VERSION ""

NS_ :

BS_:

BU_: GW ESC EPS VCU EKS AVAS

VAL_TABLE_ RollingCounter_0x132 15 "Invalid";
VAL_TABLE_ ESC_HSA_Control_Status 1 "active" 0 "inactive";
VAL_TABLE_ ESC_HSA_Status_Fault 1 " HSA Defective" 0 "HSA Normale";
VAL_TABLE_ ESC_TcsDisableSts 3 "signal invalid" 2 "reservred" 1 "disabled" 0 "enabled";
VAL_TABLE_ ESC_TcsCtrlActv 1 "active" 0 "inactive";
VAL_TABLE_ ESC_TcsFlgFlt 1 "failure" 0 "no failure";
VAL_TABLE_ ESC_EscDisableSts 1 "disabled" 0 "enabled";
VAL_TABLE_ ESC_EscCtrlActv 1 "active" 0 "inactive";
VAL_TABLE_ ESC_EscFlgFlt 1 "failure" 0 "no failure";
VAL_TABLE_ ESC_HBAFlgFlt 1 "failure" 0 "no failure";
VAL_TABLE_ ESC_HbaCtrlActv 1 "active" 0 "inactive";
VAL_TABLE_ ESC_SlopeGradeAngle 255 "Invalid";
VAL_TABLE_ ESC_MasterCylinderPressure 4095 "Invalid";
VAL_TABLE_ RollingCounter_0x142 15 "Invalid";
VAL_TABLE_ AbsDiagSessionLampReq_Reserved 1 "lamp on" 0 "lamp off";
VAL_TABLE_ ABS_AbsCtrlActv 1 "active" 0 "inactive";
VAL_TABLE_ ABS_EbdFlgFlt 1 "failure" 0 "no failure";
VAL_TABLE_ ABS_AbsFlgFlt 1 "failure" 0 "no failure";
VAL_TABLE_ ABS_ESS_Active 1 "active" 0 "inactive";
VAL_TABLE_ ABS_LowBrakeFluid 1 "failure" 0 "no failure";
VAL_TABLE_ RollingCounter_0x332 15 "Invalid";
VAL_TABLE_ ABS_LFWhlSpdRaw 32767 "Invalid";
VAL_TABLE_ ABS_LFWhlSpdRawValid 1 "Valid" 0 "Invalid";
VAL_TABLE_ ABS_RFWhlSpdRaw 32767 "Invalid";
VAL_TABLE_ ABS_RFWhlSpdRawValid 1 "Valid" 0 "Invalid";
VAL_TABLE_ RollingCounter_0x342 15 "Invalid";
VAL_TABLE_ ABS_LRWhlSpdRaw 32767 "Invalid";
VAL_TABLE_ ABS_LRWhlSpdRawValid 1 "Valid" 0 "Invalid";
VAL_TABLE_ ABS_RRWhlSpdRaw 32767 "Invalid";
VAL_TABLE_ ABS_RRWhlSpdRawValid 1 "Valid" 0 "Invalid";
VAL_TABLE_ ABS_VehSpd 32767 "Invalid";
VAL_TABLE_ ABS_VehSpdValid 1 "Valid" 0 "Invalid";
VAL_TABLE_ ABS_WssLFPulseCounter 32767 "Invalid";
VAL_TABLE_ ABS_WssLFPulseCounterValid 1 "Valid" 0 "Invalid";
VAL_TABLE_ ABS_WssRFPulseCounter 32767 "Invalid";
VAL_TABLE_ ABS_WssRFPulseCounterValid 1 "Valid" 0 "Invalid";
VAL_TABLE_ ABS_WssLRPulseCounter 32767 "Invalid";
VAL_TABLE_ ABS_WssLRPulseCounterValid 1 "Valid" 0 "Invalid";
VAL_TABLE_ ABS_WssRRPulseCounter 32767 "Invalid";
VAL_TABLE_ ABS_WssRRPulseCounterValid 1 "Valid" 0 "Invalid";
VAL_TABLE_ RollingCounter_0x3E2 15 "Invalid";
VAL_TABLE_ ESC_LateralACC 255 "Invalid";
VAL_TABLE_ ESC_LateralACC_Valid 1 "Valid" 0 "Invalid";
VAL_TABLE_ ESC_LongitudeACC 1023 "Invalid";
VAL_TABLE_ ESC_LongitudeACC_Valid 1 "Valid" 0 "Invalid";
VAL_TABLE_ ESC_VehDynYawRate 16383 "Invalid";
VAL_TABLE_ ESC_VehDynYawRate_Valid 1 "Valid" 0 "Invalid";
VAL_TABLE_ RollingCounter_0x3F2 15 "Invalid";
VAL_TABLE_ ESC_VehicleACC 1023 "Invalid";
VAL_TABLE_ ESC_VehicleACC_Valid 1 "Valid" 0 "Invalid";
VAL_TABLE_ RollingCounter_362 15 "Invalid";
VAL_TABLE_ ESC_RegenDragCtrlStatus 1 "active" 0 "inactive";
VAL_TABLE_ ESC_RegenBrakeCtrlStatus 1 "active" 0 "inactive";
VAL_TABLE_ ESC_TorqReqMode 3 "Reserved" 2 "Regen mode" 1 "TCS mode" 0 "Normal mode";
VAL_TABLE_ ESC_TorqRequestVal 65535 "Invalid";
VAL_TABLE_ ESC_FLTirePressAlarm 1 "Pressure warning" 0 "No warning";
VAL_TABLE_ ESC_FRTirePressAlarm 1 "Pressure warning" 0 "No warning";
VAL_TABLE_ ESC_RLTirePressAlarm 1 "Pressure warning" 0 "No warning";
VAL_TABLE_ ESC_RRTirePressAlarm 1 "Pressure warning" 0 "No warning";
VAL_TABLE_ ESC_iTPMS_Err 1 "Error" 0 "No error";
VAL_TABLE_ ESC_iTPMS_WarnLampAct 1 "Active" 0 "Inactive";
VAL_TABLE_ ESC_iTPMSResetProhibit 3 "prohibit 3 (System error)" 2 "prohibit 2 (Vehicle speed >0 km/h)" 1 "prohibit 1 (Tire statue is changing)" 0 "Not prohibit";
VAL_TABLE_ ESC_iTPMSResetSts 4 "Reset fail" 3 "Reset finish" 2 "Reset ongoing" 1 "Reset start" 0 "Idle";
VAL_TABLE_ Rolling_counter_0x17E 15 "Invalid";
VAL_TABLE_ SAS_SteerWheelAngle 65535 "Invalid";
VAL_TABLE_ SAS_SteeringAngleValid 1 "Valid" 0 "Invalid";
VAL_TABLE_ SAS_SASStsSnsr 1 "sensor value valid" 0 "sensor value Invalid";
VAL_TABLE_ SAS_SteerWhlRotSpd 16383 "Invalid";
VAL_TABLE_ SAS_SteerWhlRotSpdStatus 1 "Valid" 0 "Invalid";
VAL_TABLE_ SAS_Calibrated 1 "Calibrated" 0 "Not Calibrated";
VAL_TABLE_ SAS_SASFailure 1 "No Failure" 0 "Failure";
VAL_TABLE_ Rolling_counter_0x37E 15 "Invalid";
VAL_TABLE_ EPS_SteeringTorque 4095 "Invalid";
VAL_TABLE_ EPS_TorqSensorStatus 1 "Invalid" 0 "Valid";
VAL_TABLE_ EPS_EpsFailed 1 "failed" 0 "not failed";
VAL_TABLE_ EPS_Mode 3 " Invalid" 1 "low assist" 0 "full assist";
VAL_TABLE_ RollingCounter_0x108 15 "Invalid";
VAL_TABLE_ EKS_DriveModeReq_reserved 1 "press" 0 "no press";
VAL_TABLE_ EKS_TargetGearReq 7 "Reserved" 4 "Invalid" 3 "D" 2 "N" 1 "R" 0 "P reserved";
VAL_TABLE_ EKS_Fault 5 "Received Date from VCU is invalid" 4 "Supply voltage failure" 3 "Position sensor failure" 2 "CAN communication fail" 1 "Shifter failure" 0 "normal";
VAL_TABLE_ RollingCounter_0x269 15 "Invalid";
VAL_TABLE_ VCU_VehicleHVStatus 3 "Reserved" 2 "ReadyToDrive" 1 "HV On" 0 "Not ready";
VAL_TABLE_ VCU_ActualGear 7 "Fault" 6 "Reserved" 5 "Reserved" 4 "Reserved" 3 "D" 2 "N" 1 "R" 0 "P reserved";
VAL_TABLE_ VCU_ActualGearValid 1 "Invalid" 0 "Valid";
VAL_TABLE_ VCU_AccPedalPosition 255 "Invalid";
VAL_TABLE_ VCU_AccPedalPositionValid 1 "Invalid" 0 "Valid";
VAL_TABLE_ VCU_TqReductionRqstResponse 1 "active" 0 "inactive";
VAL_TABLE_ VCU_BrakePedalSts 3 "Invalid" 2 "Reserved" 1 "pressed" 0 "Not pressed";
VAL_TABLE_ Rolling_Counter_0x20C 15 "Invalid";
VAL_TABLE_ IPC_ODO 1048575 "Invalid";
VAL_TABLE_ IPC_TripA 65535 "Invalid";
VAL_TABLE_ IPC_AverageSpeedTripA 4095 "Invalid";
VAL_TABLE_ IPC_AverageConsumptionTripA 1023 "Invalid";
VAL_TABLE_ IPC_ParkBrakeSts 3 "Invalid" 2 "Reserved" 1 "Applied" 0 "Released";
VAL_TABLE_ IPC_VehSpd 32767 "Invalid";
VAL_TABLE_ IPC_TireLearningReq_reserved 3 "Reserved" 2 "Reserved" 1 "Requset" 0 "No requset";
VAL_TABLE_ IPC_TireResetReq 3 "Reserved" 2 "Reserved" 1 "Requset to reset" 0 "No requset";
VAL_TABLE_ IPC_Sec 63 "Invalid";
VAL_TABLE_ IPC_Min 63 "Invalid";
VAL_TABLE_ IPC_Hour 31 "Invalid";
VAL_TABLE_ IPC_Day 31 "Invalid";
VAL_TABLE_ IPC_Month 15 "Invalid";
VAL_TABLE_ IPC_Year 255 "Invalid";
VAL_TABLE_ IPC_SelfCheckStatus 1 "self-check finish" 0 "self-checking";
VAL_TABLE_ CCU_ExternalTemperature 255 "Invaild";
VAL_TABLE_ CCU_ExternalTemperatureFailSts 1 "invalid" 0 "valid";
VAL_TABLE_ MHU_St_DimmingIPC 15"Invalid" 14"Level 15" 13 "Level 14" 12 "Level 13" 11 "Level 12" 10 "Level 11" 9"Level 10" 8 "Level 9" 7 "Level 8" 6 "Level 7" 5 "Level 6" 4 "Level 5" 3 "Level 4" 2 "Level 3" 1"Level 2" 0"Level 1";
VAL_TABLE_ Rolling_Counter_0x403 15 "Invalid";
VAL_TABLE_ MHU_SET_TCS_OnOff 0 "OFF (keep sending for 2 seconds)" 1 "ON (keep sending for 2 seconds)" 2 "No action" 3 "Invalid";
VAL_TABLE_ MHU_SET_DrivingModeSwitch 3 "sport mode (should be hold during 1 second)" 2 "normal mode (should be hold during 1 second)" 1 "eco mode (should be hold during 1 second)" 0 "no change request";
VAL_TABLE_ MHU_SET_RegenLevel 3 "No action" 2 "High" 1 "Low" 0 "none";
VAL_TABLE_ MHU_VCU_CreepDisable_stt 0 "No request" 1 "Creep Disable request" 2 "Reserved" 3 "Invalid";
VAL_TABLE_ MHU_HVACTurnON 0 "No request" 1 "ON" 2 "Reserved" 3 "Invalid";
VAL_TABLE_ MHU_ChargeScheduleSet 0 "Disabled" 1 "Enabled" 2 "No Action" 3 "Reserved";
VAL_TABLE_ MHU_ChargingRequest 0 "Reserved" 1 "Request scheduled start charging" 2 "Request stop" 3 "No effect";
VAL_TABLE_ MHU_ValetMode_Activation 0 "Inactive" 1 "Active" 254 "Reserved" 255 "Invalid";
VAL_TABLE_ BCM_STAT_DoorAjarDriver 3 "Signal invalid" 2 "Reserved" 1 "Opened" 0 "Closed";
VAL_TABLE_ BCM_PosLmpSts 0 "OFF" 1 "ON" 2 "Fault (Reserved)" 3 "Signal Invalid";
VAL_TABLE_ Rolling_Counter_0x10a 15 "Invalid";
VAL_TABLE_ BCM_LVTop_up 1 "start Top up" 0 "stop Top up";
VAL_TABLE_ Rolling_Counter_0x112 15 "Invalid";
VAL_TABLE_ STAT_Terminal 7 "Signal invalid" 6 "Reserved" 5 "Reserved" 4 "SW update OTA (Not used in VFe34)" 3 "Engine start (eMotor running)" 2 "ON (Driver Present)" 1 "ACC (Park)" 0 "OFF(Comfort Enable)";
VAL_TABLE_ STAT_CL30s_L_Reserved 3 "Signal invalid" 2 "Failure" 1 "ON" 0 "OFF";
VAL_TABLE_ RollingCounter_0x85 15 "Invalid";
VAL_TABLE_ ACM_Crash_Sts 3 "Invalid Value" 2 "Invalid Value" 1 "Crash_Detected" 0 "No_Event";
VAL_TABLE_ ACM_Airbag_Deployment_Status 3 "Invalid Value" 2 "Invalid Value" 1 "Airbag_Deployment" 0 "No_Airbag_Deployment";
VAL_TABLE_ ACM_Crash_Intensity 7 "Invalid_Value" 6 "Invalid_Value" 5 "Invalid_Value" 4 "Invalid_Value" 3 "Crash_Intensity_3" 2 "Crash_Intensity_2" 1 "Crash_Intensity_1" 0 "No_Crash";
VAL_TABLE_ ACM_Front_Crash 3 "Invalid Value" 2 "Invalid Value" 1 "Front_Crash_Detected" 0 "No_Event";
VAL_TABLE_ ACM_DriverSide_Crash 3 "Invalid Value" 2 "Invalid Value" 1 "Driverside_Crash_Detected" 0 "No_Event";
VAL_TABLE_ ACM_PassSide_Crash 3 "Invalid Value" 2 "Invalid Value" 1 "PassSide_Crash_Detected" 0 "No_Event";
VAL_TABLE_ ACM_Rear_Crash 3 "Invalid Value" 2 "Invalid Value" 1 "Rear_Crash_Detected" 0 "No_Event";
VAL_TABLE_ ACM_Rollover_Crash 3 "Invalid Value" 2 "Invalid Value" 1 "Rollover_Crash_Detected" 0 "No_Event";
VAL_TABLE_ Rolling_Counter_0x381 15 "Invalid";
VAL_TABLE_ ACM_Seat_Occupancy_Passenger 3 "Failure" 2 "Not_Available" 1 "Seat Occupied" 0 "Seat_Not_Occupied";
VAL_TABLE_ ACM_Seat_Occupancy_2nd_Row_Dri_reserved 3 "Failure" 2 "Not_Available" 1 "Seat Occupied" 0 "Seat_Not_Occupied";
VAL_TABLE_ ACM_Seat_Occupancy_2nd_Row_Pas_reserved 3 "Failure" 2 "Not_Available" 1 "Seat Occupied" 0 "Seat_Not_Occupied";
VAL_TABLE_ ACM_Seat_Occupancy_2nd_Row_Mid_reserved 3 "Failure" 2 "Not_Available" 1 "Seat Occupied" 0 "Seat_Not_Occupied";
VAL_TABLE_ ACM_Seat_Belt_Status_Passenger 3 "Failure" 2 "Not_Available" 1 "Buckled" 0 "Not_buckled";
VAL_TABLE_ ACM_Seat_Belt_Status_Driver 3 "Failure" 2 "Not_Available" 1 "Buckled" 0 "Not_buckled";
VAL_TABLE_ ACM_Seat_Belt_Status_2nd_Row_Dri_reserved 3 "Failure" 2 "Not_Available" 1 "Buckled" 0 "Not_buckled";
VAL_TABLE_ ACM_Seat_Belt_Status_2nd_Row_Mid_reserved 3 "Failure" 2 "Not_Available" 1 "Buckled" 0 "Not_buckled";
VAL_TABLE_ ACM_Seat_Belt_Status_2nd_Row_Pas_reserved 3 "Failure" 2 "Not_Available" 1 "Buckled" 0 "Not_buckled";
VAL_TABLE_ ACM_Seat_Belt_Status_3rd_Row_Dri_reserved 3 "Failure" 2 "Not_Available" 1 "Buckled" 0 "Not_buckled";
VAL_TABLE_ ACM_Seat_Belt_Status_3rd_Row_Pas_reserved 3 "Failure" 2 "Not_Available" 1 "Buckled" 0 "Not_buckled";
VAL_TABLE_ Rolling_Counter_0x215 15 "Invalid";
VAL_TABLE_ BMS_SOE 255 "Invalid";
VAL_TABLE_ BMS_HWCrash_Sts 1 "Crash " 0 "No Crash";
VAL_TABLE_ BMS_HVIL_STS 2 "short to ground" 1 "Open & short to battery" 0 "Closed";
VAL_TABLE_ BMS_IGN_Sts 1 "ON " 0 "OFF";
VAL_TABLE_ BMS_Sys_STS 8 "Invalid" 7 "Failure, unable to operate" 6 "BCU Sleep mode" 5 "Successful Power Down" 4 "Power Down process" 3 "Successful Power Down of HV" 2 "Successful High Voltage Power Up" 1 "Self-check passes, can be high-voltage" 0 "Initialization of power on, self-checking";
VAL_TABLE_ BMS_HVOnOff_STS 3 "Fail to HV on " 2 "HV On " 1 "Precharge " 0 "HV Off";
VAL_TABLE_ BMS_Balance_STS 1 "active " 0 "Inactive";
VAL_TABLE_ BMS_SocActual_EST 1023 "Invalid";
VAL_TABLE_ BMS_BatBalance_ERR 1 "normal " 0 "Error";
VAL_TABLE_ BMS_ISU_Status 3 "Level3(<100 Ohms/V)" 2 "Level2(<200 Ohms/V)" 1 "Level1 <500 Ohms/V ~ >200 Ohms/V" 0 "Normal (> 500 Ohms/V)";
VAL_TABLE_ BMS_ERR_LEV 7 "Battery locked -Reserved" 6 "Fault, needs Shutdown and Wakeup" 5 "Emergency off condition" 4 "Delayed power down with FTTI" 3 "Power down without FTTI" 2 "Limp Home" 1 " Warning (any warning in system)" 0 "No error";
VAL_TABLE_ BMS_SOH 255 "Invalid";
VAL_TABLE_ BMS_HV_Sts 4 "AC Charge" 3 "Super Fast Charge" 2 "HV ON" 1 "Precharge" 0 "HV Off";
VAL_TABLE_ Rolling_Counter_0x1F8 15 "Invalid";
VAL_TABLE_ EDS_output_trq_FR 65535 "Invalid";
VAL_TABLE_ EDS_output_trqValid_FR 1 "valid" 0 "invalid";
VAL_TABLE_ EDS_Spd_FR 65535 "Invalid";
VAL_TABLE_ EDS_SpdValid_FR 1 "valid" 0 "invalid";
VAL_TABLE_ EDS_MotorDriveSts_FR 3 "Invaild" 2 "regen control" 1 "Drive control" 0 "Zero control";
VAL_TABLE_ EDS_Work_STS_FR 15 "invaild" 14 "power off" 13 "Failure" 12 "after run" 11 "shut down" 5 "HVReady" 4 "normal" 3 "precharge" 2 "standby" 1 "init" 0 "default";
VAL_TABLE_ EDS_powoff_req_FR 1 "(Request high voltage power down)" 0 "(No request)";
VAL_TABLE_ VCU_DriveCoolWaterPumpSts 5 "Reserved" 4 "Other error" 3 "Overtemperature" 2 "Locked-rotor" 1 "Idle" 0 "Normal";
VAL_TABLE_ VCU_DriveCoolWaterDuty 127 "Invalid";
VAL_TABLE_ VCU_BatteryWaterPumpSts_reserved 5 "Reserved" 4 "Other error" 3 "Overtemperature" 2 "Locked-rotor" 1 "Idle" 0 "Normal";
VAL_TABLE_ VCU_BatteryWaterPumpDuty_reserved 127 "Invalid";
VAL_TABLE_ VCU_DriveMode 7 "Invalid" 6 "Reserved" 5 "Reserved" 4 "Reserved" 3 "Reserved" 2 "Sport mode" 1 "ECO mode" 0 "Normal mode";
VAL_TABLE_ VCU_ActualGear 7 "Fault" 6 "Reserved" 5 "Reserved" 4 "Reserved" 3 "D" 2 "N" 1 "R" 0 "P reserved";
VAL_TABLE_ VCU_ACTGearValid 1 "nvalid" 0 "Valid";
VAL_TABLE_ VCU_AccPedal1OutRange 1 "Error" 0 "Normal";
VAL_TABLE_ VCU_AccPedal2OutRange 1 "Error" 0 "Normal";
VAL_TABLE_ VCU_BrkPedal1OutRange 1 "Error" 0 "Normal";
VAL_TABLE_ VCU_BrkPedal2OutRange 1 "Error" 0 "Normal";
VAL_TABLE_ VCU_BrkPedalPct 255 "Invalid";
VAL_TABLE_ VCU_AccPedalPosition 255 "Invalid";
VAL_TABLE_ VCU_AccPedalPositionValid 1 "Invalid" 0 "Valid";
VAL_TABLE_ VCU_SocDisplay_EST 127 "Invalid";
VAL_TABLE_ VCU_PowerLimit 1 "Limit" 0 "No Limit";
VAL_TABLE_ VCU_CruiseCtrlSts 3 "takeover mode" 2 "Pre cruise(lamp flash)" 1 "Cruise on(lamp on)" 0 "Cruise off(lamp off)";
VAL_TABLE_ VCU_LowSOC_ERR 1 "Error" 0 "No Error";
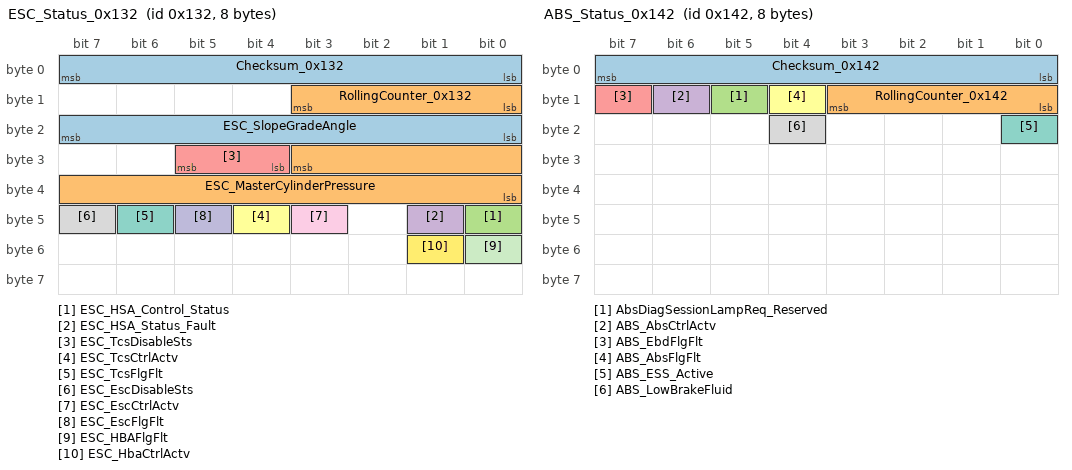
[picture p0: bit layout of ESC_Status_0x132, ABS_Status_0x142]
BO_ 306 ESC_Status_0x132: 8 ESC
 SG_ Checksum_0x132 : 7|8@0+ (1,0) [0|255] "" GW,VCU
 SG_ RollingCounter_0x132 : 11|4@0+ (1,0) [0|15] "" GW,VCU
 SG_ ESC_HSA_Control_Status : 40|1@0+ (1,0) [0|1] "" GW,VCU
 SG_ ESC_HSA_Status_Fault : 41|1@0+ (1,0) [0|1] "" GW,VCU
 SG_ ESC_TcsDisableSts : 29|2@0+ (1,0) [0|3] "" GW,VCU
 SG_ ESC_TcsCtrlActv : 44|1@0+ (1,0) [0|1] "" GW,VCU
 SG_ ESC_TcsFlgFlt : 46|1@0+ (1,0) [0|1] "" GW,VCU
 SG_ ESC_EscDisableSts : 47|1@0+ (1,0) [0|1] "" GW,VCU
 SG_ ESC_EscCtrlActv : 43|1@0+ (1,0) [0|1] "" GW,VCU
 SG_ ESC_EscFlgFlt : 45|1@0+ (1,0) [0|1] "" GW,VCU
 SG_ ESC_HBAFlgFlt : 48|1@0+ (1,0) [0|1] "" GW,VCU
 SG_ ESC_HbaCtrlActv : 49|1@0+ (1,0) [0|1] "" GW,VCU
 SG_ ESC_SlopeGradeAngle : 23|8@0+ (0.35433,-45) [-45|45] "deg" GW,VCU
 SG_ ESC_MasterCylinderPressure : 27|12@0+ (0.1,-100) [-100|309.4] "bar" GW,VCU
BO_ 322 ABS_Status_0x142: 8 ESC
 SG_ Checksum_0x142 : 7|8@0+ (1,0) [0|255] "" GW,VCU
 SG_ RollingCounter_0x142 : 11|4@0+ (1,0) [0|15] "" GW,VCU
 SG_ AbsDiagSessionLampReq_Reserved : 13|1@0+ (1,0) [0|1] "" GW,VCU
 SG_ ABS_AbsCtrlActv : 14|1@0+ (1,0) [0|1] "" GW,VCU
 SG_ ABS_EbdFlgFlt : 15|1@0+ (1,0) [0|1] "" GW,VCU
 SG_ ABS_AbsFlgFlt : 12|1@0+ (1,0) [0|1] "" GW,VCU
 SG_ ABS_ESS_Active : 16|1@0+ (1,0) [0|1] "" GW,VCU
 SG_ ABS_LowBrakeFluid : 20|1@0+ (1,0) [0|1] "" GW,VCU
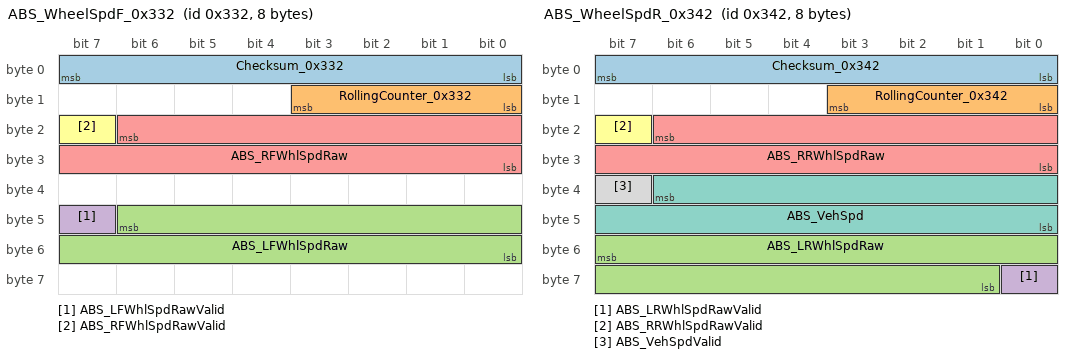
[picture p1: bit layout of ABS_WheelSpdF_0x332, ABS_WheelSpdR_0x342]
BO_ 818 ABS_WheelSpdF_0x332: 8 ESC
 SG_ Checksum_0x332 : 7|8@0+ (1,0) [0|255] "" VCU
 SG_ RollingCounter_0x332 : 11|4@0+ (1,0) [0|15] "" VCU
 SG_ ABS_LFWhlSpdRaw : 46|15@0+ (0.01,0) [0|327.66] "kph" VCU
 SG_ ABS_LFWhlSpdRawValid : 47|1@0+ (1,0) [0|1] "" VCU
 SG_ ABS_RFWhlSpdRaw : 22|15@0+ (0.01,0) [0|327.66] "kph" VCU
 SG_ ABS_RFWhlSpdRawValid : 23|1@0+ (1,0) [0|1] "" VCU
BO_ 834 ABS_WheelSpdR_0x342: 8 ESC
 SG_ Checksum_0x342 : 7|8@0+ (1,0) [0|255] "" GW,EPS,VCU,EKS,AVAS
 SG_ RollingCounter_0x342 : 11|4@0+ (1,0) [0|15] "" GW,EPS,VCU,EKS,AVAS
 SG_ ABS_LRWhlSpdRaw : 55|15@0+ (0.01,0) [0|327.66] "kph" GW,VCU,AVAS
 SG_ ABS_LRWhlSpdRawValid : 56|1@0+ (1,0) [0|1] "" GW,VCU,AVAS
 SG_ ABS_RRWhlSpdRaw : 22|15@0+ (0.01,0) [0|327.66] "kph" GW,VCU,AVAS
 SG_ ABS_RRWhlSpdRawValid : 23|1@0+ (1,0) [0|1] "" GW,VCU,AVAS
 SG_ ABS_VehSpd : 38|15@0+ (0.01,0) [0|327.66] "kph" GW,EPS,VCU,EKS,AVAS
 SG_ ABS_VehSpdValid : 39|1@0+ (1,0) [0|1] "" GW,EPS,VCU,EKS,AVAS
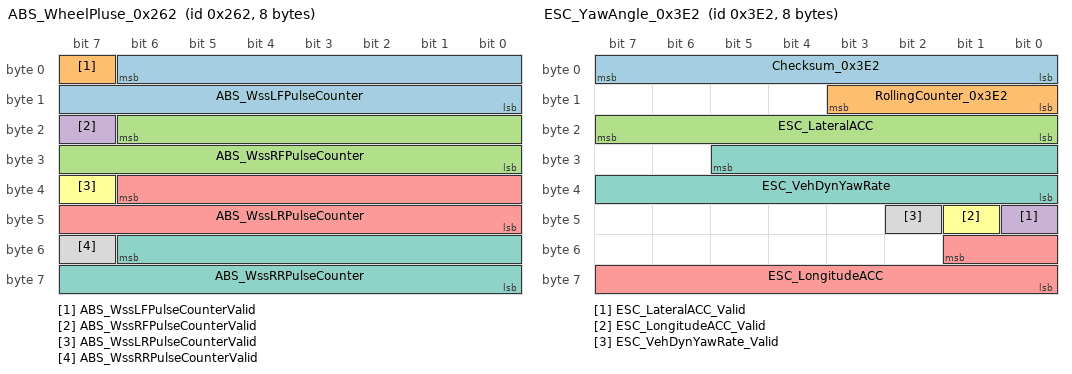
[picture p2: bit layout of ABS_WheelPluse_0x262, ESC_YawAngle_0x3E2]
BO_ 610 ABS_WheelPluse_0x262: 8 ESC
 SG_ ABS_WssLFPulseCounter : 6|15@0+ (1,0) [0|32766] "pluse" Vector__XXX
 SG_ ABS_WssLFPulseCounterValid : 7|1@0+ (1,0) [0|1] "" Vector__XXX
 SG_ ABS_WssRFPulseCounter : 22|15@0+ (1,0) [0|32766] "pluse" Vector__XXX
 SG_ ABS_WssRFPulseCounterValid : 23|1@0+ (1,0) [0|1] "" Vector__XXX
 SG_ ABS_WssLRPulseCounter : 38|15@0+ (1,0) [0|32766] "pluse" Vector__XXX
 SG_ ABS_WssLRPulseCounterValid : 39|1@0+ (1,0) [0|1] "" Vector__XXX
 SG_ ABS_WssRRPulseCounter : 54|15@0+ (1,0) [0|32766] "pluse" Vector__XXX
 SG_ ABS_WssRRPulseCounterValid : 55|1@0+ (1,0) [0|1] "" Vector__XXX
BO_ 994 ESC_YawAngle_0x3E2: 8 ESC
 SG_ Checksum_0x3E2 : 7|8@0+ (1,0) [0|255] "" GW
 SG_ RollingCounter_0x3E2 : 11|4@0+ (1,0) [0|15] "" GW
 SG_ ESC_LateralACC : 23|8@0+ (0.01587,-2.0193) [-2.0193|2.0193] "g" GW
 SG_ ESC_LateralACC_Valid : 40|1@0+ (1,0) [0|1] "" GW
 SG_ ESC_LongitudeACC : 49|10@0+ (0.00392,-1.9929) [-1.9929|1.9929] "g" GW
 SG_ ESC_LongitudeACC_Valid : 41|1@0+ (1,0) [0|1] "" GW
 SG_ ESC_VehDynYawRate : 29|14@0+ (0.03125,-256) [-256|255.96875] "deg/s" GW
 SG_ ESC_VehDynYawRate_Valid : 42|1@0+ (1,0) [0|1] "" GW
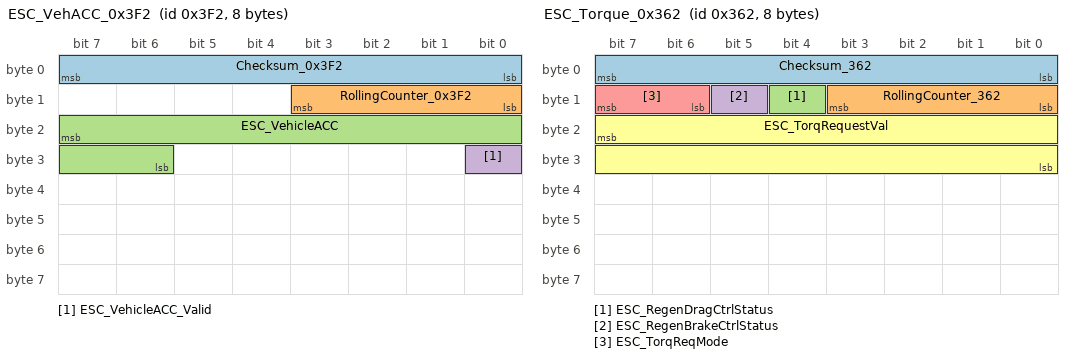
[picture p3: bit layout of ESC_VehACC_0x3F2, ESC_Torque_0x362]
BO_ 1010 ESC_VehACC_0x3F2: 8 ESC
 SG_ Checksum_0x3F2 : 7|8@0+ (1,0) [0|255] "" Vector__XXX
 SG_ RollingCounter_0x3F2 : 11|4@0+ (1,0) [0|15] "" Vector__XXX
 SG_ ESC_VehicleACC : 23|10@0+ (0.00392,-1.9929) [-1.9929|1.9929] "g" Vector__XXX
 SG_ ESC_VehicleACC_Valid : 24|1@0+ (1,0) [0|1] "" Vector__XXX
BO_ 866 ESC_Torque_0x362: 8 ESC
 SG_ Checksum_362 : 7|8@0+ (1,0) [0|255] "" VCU
 SG_ RollingCounter_362 : 11|4@0+ (1,0) [0|15] "" VCU
 SG_ ESC_RegenDragCtrlStatus : 12|1@0+ (1,0) [0|1] "" VCU
 SG_ ESC_RegenBrakeCtrlStatus : 13|1@0+ (1,0) [0|1] "" VCU
 SG_ ESC_TorqReqMode : 15|2@0+ (1,0) [0|3] "" VCU
 SG_ ESC_TorqRequestVal : 23|16@0+ (0.05,-1000) [-1000|1000] "Nm" VCU
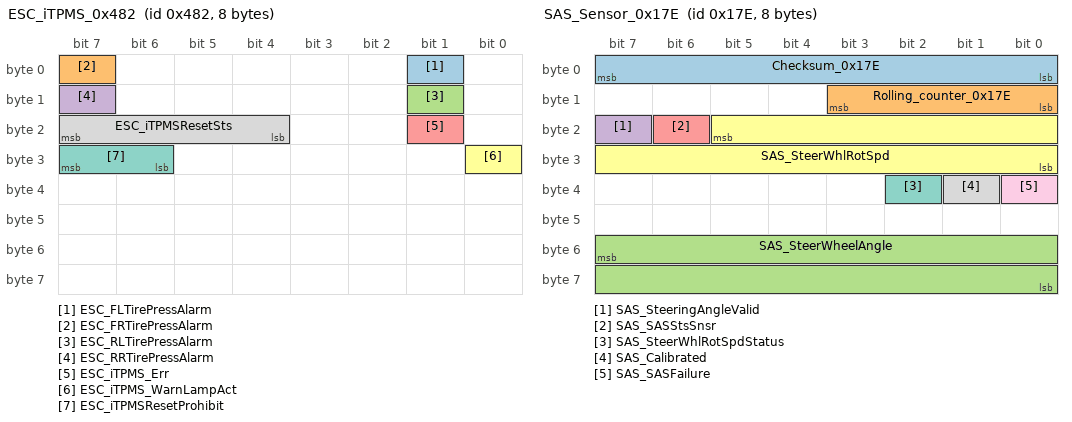
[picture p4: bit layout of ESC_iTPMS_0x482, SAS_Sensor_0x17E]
BO_ 1154 ESC_iTPMS_0x482: 8 ESC
 SG_ ESC_FLTirePressAlarm : 1|1@0+ (1,0) [0|1] "" GW
 SG_ ESC_FRTirePressAlarm : 7|1@0+ (1,0) [0|1] "" GW
 SG_ ESC_RLTirePressAlarm : 9|1@0+ (1,0) [0|1] "" GW
 SG_ ESC_RRTirePressAlarm : 15|1@0+ (1,0) [0|1] "" GW
 SG_ ESC_iTPMS_Err : 17|1@0+ (1,0) [0|1] "" GW
 SG_ ESC_iTPMS_WarnLampAct : 24|1@0+ (1,0) [0|1] "" GW
 SG_ ESC_iTPMSResetProhibit : 31|2@0+ (1,0) [0|3] "" GW
 SG_ ESC_iTPMSResetSts : 23|4@0+ (1,0) [0|15] "" GW
BO_ 382 SAS_Sensor_0x17E: 8 EPS
 SG_ Checksum_0x17E : 7|8@0+ (1,0) [0|255] "" GW,ESC
 SG_ Rolling_counter_0x17E : 11|4@0+ (1,0) [0|15] "" GW,ESC
 SG_ SAS_SteerWheelAngle : 55|16@0+ (0.0238,-780) [-780|779.7] "deg" GW,ESC
 SG_ SAS_SteeringAngleValid : 23|1@0+ (1,0) [0|1] "" GW,ESC
 SG_ SAS_SASStsSnsr : 22|1@0+ (1,0) [0|1] "" GW,ESC
 SG_ SAS_SteerWhlRotSpd : 21|14@0+ (0.125,-1024) [-1024|1023.75] "degs" GW,ESC
 SG_ SAS_SteerWhlRotSpdStatus : 34|1@0+ (1,0) [0|1] "" GW,ESC
 SG_ SAS_Calibrated : 33|1@0+ (1,0) [0|1] "" GW,ESC
 SG_ SAS_SASFailure : 32|1@0+ (1,0) [0|1] "" GW,ESC
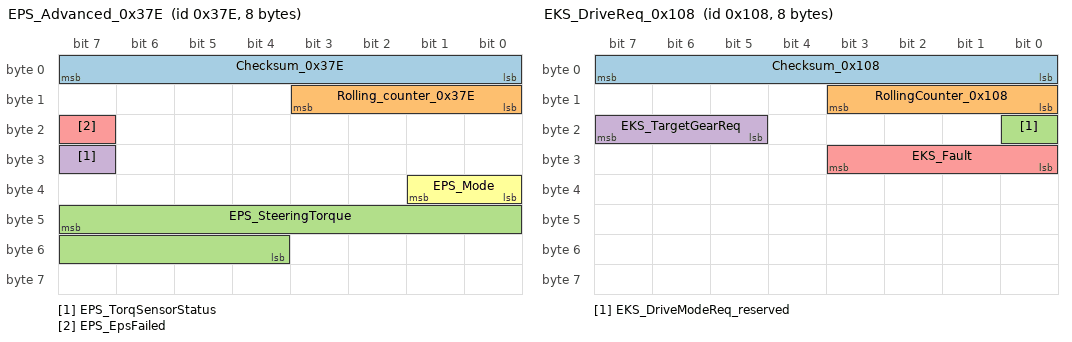
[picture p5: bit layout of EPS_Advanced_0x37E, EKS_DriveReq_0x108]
BO_ 894 EPS_Advanced_0x37E: 8 EPS
 SG_ Checksum_0x37E : 7|8@0+ (1,0) [0|255] "" GW,VCU
 SG_ Rolling_counter_0x37E : 11|4@0+ (1,0) [0|15] "" GW,VCU
 SG_ EPS_SteeringTorque : 47|12@0+ (0.01,-20.47) [-20.47|20.47] "Nm" GW,VCU
 SG_ EPS_TorqSensorStatus : 31|1@0+ (1,0) [0|1] "" GW,VCU
 SG_ EPS_EpsFailed : 23|1@0+ (1,0) [0|1] "" GW,VCU
 SG_ EPS_Mode : 33|2@0+ (1,0) [0|3] "" GW,VCU
BO_ 264 EKS_DriveReq_0x108: 8 EKS
 SG_ Checksum_0x108 : 7|8@0+ (1,0) [0|255] "" VCU
 SG_ RollingCounter_0x108 : 11|4@0+ (1,0) [0|15] "" VCU
 SG_ EKS_DriveModeReq_reserved : 16|1@0+ (1,0) [0|1] "" VCU
 SG_ EKS_TargetGearReq : 23|3@0+ (1,0) [0|7] "" VCU
 SG_ EKS_Fault : 27|4@0+ (1,0) [0|4] "" VCU
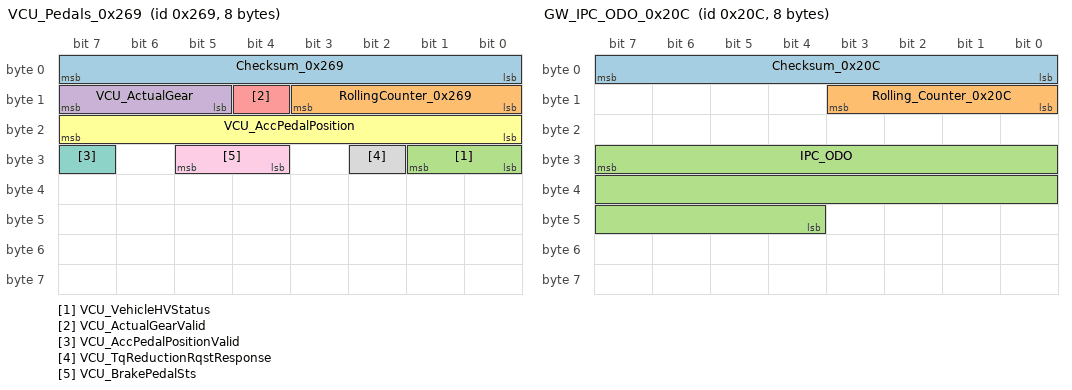
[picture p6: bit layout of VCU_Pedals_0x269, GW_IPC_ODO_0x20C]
BO_ 617 VCU_Pedals_0x269: 8 VCU
 SG_ Checksum_0x269 : 7|8@0+ (1,0) [0|255] "" GW,ESC,EPS,EKS,AVAS
 SG_ RollingCounter_0x269 : 11|4@0+ (1,0) [0|15] "" GW,ESC,EPS,EKS,AVAS
 SG_ VCU_VehicleHVStatus : 25|2@0+ (1,0) [0|3] "" GW,ESC,EPS,EKS,AVAS
 SG_ VCU_ActualGear : 15|3@0+ (1,0) [0|7] "" GW,ESC,EKS,AVAS
 SG_ VCU_ActualGearValid : 12|1@0+ (1,0) [0|1] "" GW,ESC,EKS,AVAS
 SG_ VCU_AccPedalPosition : 23|8@0+ (0.4,0) [0|100] "%" GW,ESC
 SG_ VCU_AccPedalPositionValid : 31|1@0+ (1,0) [0|1] "" GW,ESC
 SG_ VCU_TqReductionRqstResponse : 26|1@0+ (1,0) [0|1] "" GW
 SG_ VCU_BrakePedalSts : 29|2@0+ (1,0) [0|3] "" GW,ESC
BO_ 524 GW_IPC_ODO_0x20C: 8 GW
 SG_ Checksum_0x20C : 7|8@0+ (1,0) [0|255] "" ESC,EPS,VCU,EKS,AVAS
 SG_ Rolling_Counter_0x20C : 11|4@0+ (1,0) [0|15] "" ESC,EPS,VCU,EKS,AVAS
 SG_ IPC_ODO : 31|20@0+ (1,0) [0|999999] "km" ESC,EPS,VCU,EKS,AVAS
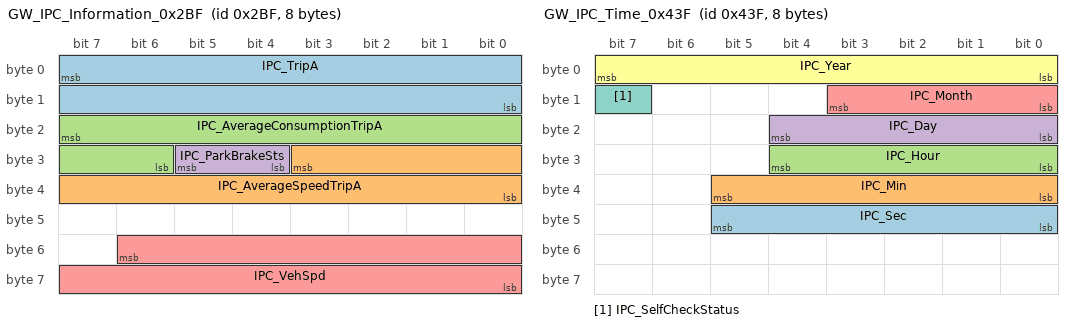
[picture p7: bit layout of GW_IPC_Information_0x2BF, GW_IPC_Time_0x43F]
BO_ 703 GW_IPC_Information_0x2BF: 8 GW
 SG_ IPC_TripA : 7|16@0+ (0.1,0) [0|999.9] "km" Vector__XXX
 SG_ IPC_AverageSpeedTripA : 27|12@0+ (0.0625,0) [0|250] "km/h" Vector__XXX
 SG_ IPC_AverageConsumptionTripA : 23|10@0+ (0.1,0) [0|100] "kwh/100km" Vector__XXX
 SG_ IPC_ParkBrakeSts : 29|2@0+ (1,0) [0|3] "" ESC
 SG_ IPC_VehSpd : 54|15@0+ (0.01,0) [0|327.66] "kph" Vector__XXX
BO_ 735 GW_IPC_TPMSReq_0x2DF: 8 GW
 SG_ IPC_TireLearningReq_reserved : 1|2@0+ (1,0) [0|3] "" Vector__XXX
 SG_ IPC_TireResetReq : 7|2@0+ (1,0) [0|3] "" ESC
BO_ 1087 GW_IPC_Time_0x43F: 8 GW
 SG_ IPC_Sec : 45|6@0+ (1,0) [0|59] "second" ESC,EPS,EKS
 SG_ IPC_Min : 37|6@0+ (1,0) [0|59] "min" ESC,EPS,EKS
 SG_ IPC_Hour : 28|5@0+ (1,0) [0|23] "hour" ESC,EPS,EKS
 SG_ IPC_Day : 20|5@0+ (1,0) [1|31] "" ESC,EPS,EKS
 SG_ IPC_Month : 11|4@0+ (1,0) [1|12] "" ESC,EPS,EKS
 SG_ IPC_Year : 7|8@0+ (1,2000) [2000|2255] "" ESC,EPS,EKS
 SG_ IPC_SelfCheckStatus : 15|1@0+ (1,0) [0|1] "" ESC,EPS,EKS
BO_ 814 GW_CCU_Info_0x32E: 8 GW
 SG_ CCU_ExternalTemperature : 7|8@0+ (0.5,-40) [-40|87] "°C" EPS,EKS,AVAS
 SG_ CCU_ExternalTemperatureFailSts : 8|1@0+ (1,0) [0|1] "" EPS,EKS,AVAS
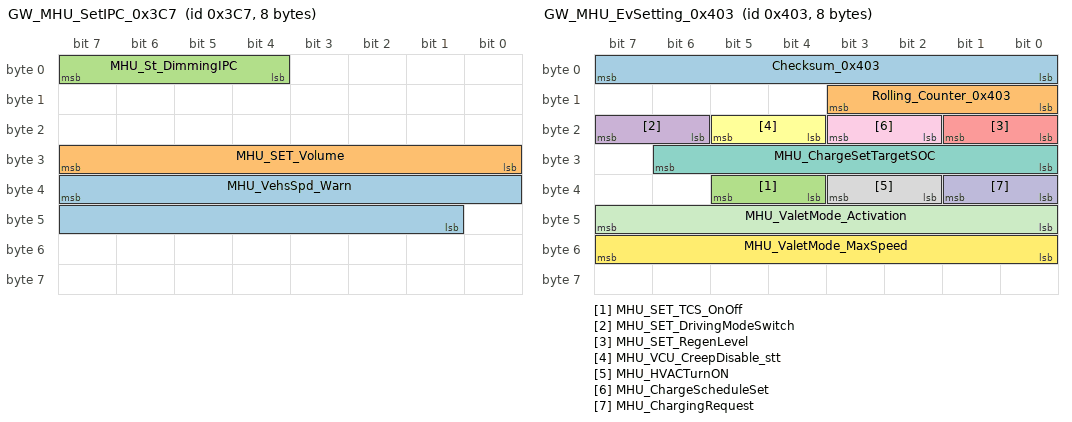
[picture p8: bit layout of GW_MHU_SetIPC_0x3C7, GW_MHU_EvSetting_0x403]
BO_ 967 GW_MHU_SetIPC_0x3C7: 8 GW
 SG_ MHU_VehsSpd_Warn : 39|15@0+ (0.01,0) [0|120] "" EKS
 SG_ MHU_SET_Volume : 31|8@0+ (1,0) [0|32] "" Vector__XXX
 SG_ MHU_St_DimmingIPC : 7|4@0+ (1,0) [0|15] "" EKS
BO_ 1027 GW_MHU_EvSetting_0x403: 8 GW
 SG_ Checksum_0x403 : 7|8@0+ (1,0) [0|255] "" ESC
 SG_ Rolling_Counter_0x403 : 11|4@0+ (1,0) [0|15] "" ESC
 SG_ MHU_SET_TCS_OnOff : 37|2@0+ (1,0) [0|3] "" ESC
 SG_ MHU_SET_DrivingModeSwitch : 23|2@0+ (1,0) [0|3] "" Vector__XXX
 SG_ MHU_SET_RegenLevel : 17|2@0+ (1,0) [0|3] "" Vector__XXX
 SG_ MHU_VCU_CreepDisable_stt : 21|2@0+ (1,0) [0|3] "" Vector__XXX
 SG_ MHU_ChargeSetTargetSOC : 30|7@0+ (1,0) [10|100] "Percentage" Vector__XXX
 SG_ MHU_HVACTurnON : 35|2@0+ (1,0) [0|3] "" Vector__XXX
 SG_ MHU_ChargeScheduleSet : 19|2@0+ (1,0) [0|3] "" Vector__XXX
 SG_ MHU_ChargingRequest : 33|2@0+ (1,0) [0|3] "" Vector__XXX
 SG_ MHU_ValetMode_Activation : 47|8@0+ (1,0) [0|254] "" Vector__XXX
 SG_ MHU_ValetMode_MaxSpeed : 55|8@0+ (1,0) [0|254] "kph" Vector__XXX
BO_ 848 GW_Body_Switch_0x350: 8 GW
 SG_ BCM_STAT_DoorAjarDriver : 7|2@0+ (1,0) [0|3] "Bit" ESC
 SG_ BCM_PosLmpSts : 15|2@0+ (1,0) [0|3] "" EKS
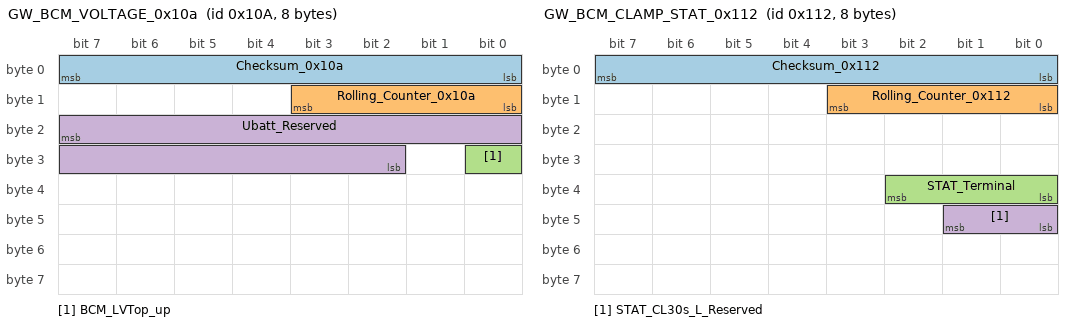
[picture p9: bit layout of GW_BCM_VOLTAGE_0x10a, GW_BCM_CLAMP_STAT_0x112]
BO_ 266 GW_BCM_VOLTAGE_0x10a: 8 GW
 SG_ Checksum_0x10a : 7|8@0+ (1,0) [0|255] "" ESC,EPS,EKS,AVAS
 SG_ Rolling_Counter_0x10a : 11|4@0+ (1,0) [0|15] "" ESC,EPS,EKS,AVAS
 SG_ BCM_LVTop_up : 24|1@0+ (1,0) [0|1] "" Vector__XXX
 SG_ Ubatt_Reserved : 23|14@0+ (0.001,3) [3|18] "V" ESC,EPS,EKS,AVAS
BO_ 274 GW_BCM_CLAMP_STAT_0x112: 8 GW
 SG_ Checksum_0x112 : 7|8@0+ (1,0) [0|255] "" ESC,EPS,EKS,AVAS
 SG_ Rolling_Counter_0x112 : 11|4@0+ (1,0) [0|15] "" ESC,EPS,EKS,AVAS
 SG_ STAT_Terminal : 34|3@0+ (1,0) [0|7] "Bit" ESC,EPS,EKS,AVAS
 SG_ STAT_CL30s_L_Reserved : 41|2@0+ (1,0) [0|3] "Bit" AVAS
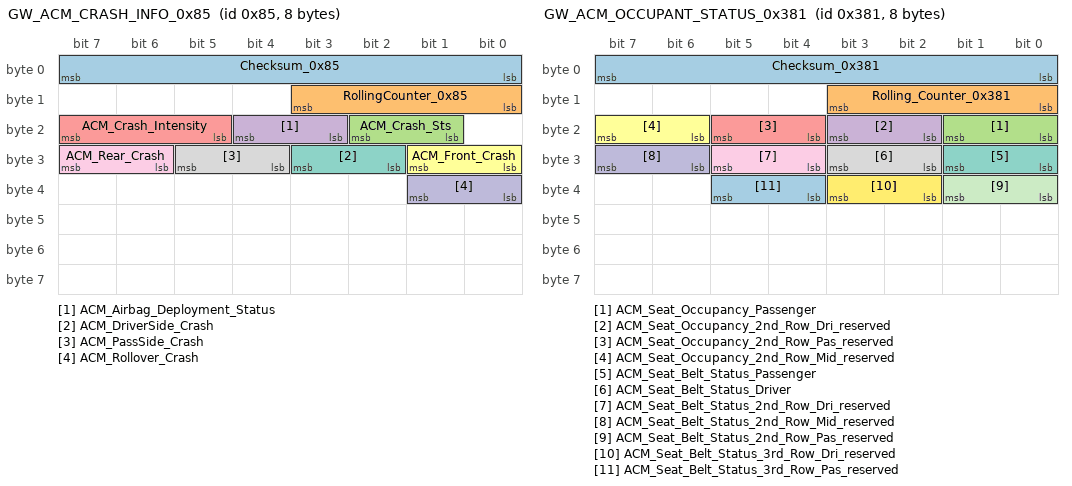
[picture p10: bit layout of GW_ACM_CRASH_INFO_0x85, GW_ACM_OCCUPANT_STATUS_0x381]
BO_ 133 GW_ACM_CRASH_INFO_0x85: 8 GW
 SG_ Checksum_0x85 : 7|8@0+ (1,0) [0|255] "" VCU
 SG_ RollingCounter_0x85 : 11|4@0+ (1,0) [0|15] "" VCU
 SG_ ACM_Crash_Sts : 18|2@0+ (1,0) [0|3] "" VCU
 SG_ ACM_Airbag_Deployment_Status : 20|2@0+ (1,0) [0|3] "" Vector__XXX
 SG_ ACM_Crash_Intensity : 23|3@0+ (1,0) [0|7] "" Vector__XXX
 SG_ ACM_Front_Crash : 25|2@0+ (1,0) [0|3] "" Vector__XXX
 SG_ ACM_DriverSide_Crash : 27|2@0+ (1,0) [0|3] "" Vector__XXX
 SG_ ACM_PassSide_Crash : 29|2@0+ (1,0) [0|3] "" Vector__XXX
 SG_ ACM_Rear_Crash : 31|2@0+ (1,0) [0|3] "" Vector__XXX
 SG_ ACM_Rollover_Crash : 33|2@0+ (1,0) [0|3] "" Vector__XXX
BO_ 897 GW_ACM_OCCUPANT_STATUS_0x381: 8 GW
 SG_ Checksum_0x381 : 7|8@0+ (1,0) [0|255] "" VCU
 SG_ Rolling_Counter_0x381 : 11|4@0+ (1,0) [0|15] "" VCU
 SG_ ACM_Seat_Occupancy_Passenger : 17|2@0+ (1,0) [0|3] "" VCU
 SG_ ACM_Seat_Occupancy_2nd_Row_Dri_reserved : 19|2@0+ (1,0) [0|3] "" VCU
 SG_ ACM_Seat_Occupancy_2nd_Row_Pas_reserved : 21|2@0+ (1,0) [0|3] "" VCU
 SG_ ACM_Seat_Occupancy_2nd_Row_Mid_reserved : 23|2@0+ (1,0) [0|3] "" VCU
 SG_ ACM_Seat_Belt_Status_Passenger : 25|2@0+ (1,0) [0|3] "" VCU
 SG_ ACM_Seat_Belt_Status_Driver : 27|2@0+ (1,0) [0|3] "" VCU
 SG_ ACM_Seat_Belt_Status_2nd_Row_Dri_reserved : 29|2@0+ (1,0) [0|3] "" VCU
 SG_ ACM_Seat_Belt_Status_2nd_Row_Mid_reserved : 31|2@0+ (1,0) [0|3] "" VCU
 SG_ ACM_Seat_Belt_Status_2nd_Row_Pas_reserved : 33|2@0+ (1,0) [0|3] "" VCU
 SG_ ACM_Seat_Belt_Status_3rd_Row_Dri_reserved : 35|2@0+ (1,0) [0|3] "" VCU
 SG_ ACM_Seat_Belt_Status_3rd_Row_Pas_reserved : 37|2@0+ (1,0) [0|3] "" VCU
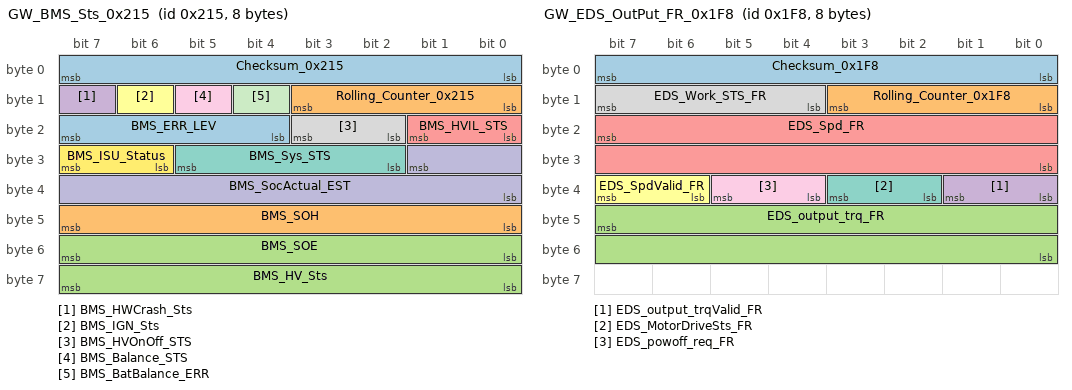
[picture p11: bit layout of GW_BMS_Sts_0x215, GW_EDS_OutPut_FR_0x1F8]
BO_ 533 GW_BMS_Sts_0x215: 8 GW
 SG_ Checksum_0x215 : 7|8@0+ (1,0) [0|255] "" EKS
 SG_ Rolling_Counter_0x215 : 11|4@0+ (1,0) [0|15] "" EKS
 SG_ BMS_SOE : 55|8@0+ (0.5,0) [0|100] "%" Vector__XXX
 SG_ BMS_HWCrash_Sts : 15|1@0+ (1,0) [0|1] "" Vector__XXX
 SG_ BMS_HVIL_STS : 17|2@0+ (1,0) [0|3] "" Vector__XXX
 SG_ BMS_IGN_Sts : 14|1@0+ (1,0) [0|1] "" Vector__XXX
 SG_ BMS_Sys_STS : 29|4@0+ (1,0) [0|15] "" Vector__XXX
 SG_ BMS_HVOnOff_STS : 19|2@0+ (1,0) [0|3] "" EKS
 SG_ BMS_Balance_STS : 13|1@0+ (1,0) [0|1] "" Vector__XXX
 SG_ BMS_SocActual_EST : 25|10@0+ (0.1,0) [0|100] "percent" Vector__XXX
 SG_ BMS_BatBalance_ERR : 12|1@0+ (1,0) [0|1] "" Vector__XXX
 SG_ BMS_ISU_Status : 31|2@0+ (1,0) [0|3] "" Vector__XXX
 SG_ BMS_ERR_LEV : 23|4@0+ (1,0) [0|15] "" Vector__XXX
 SG_ BMS_SOH : 47|8@0+ (0.5,0) [0|100] "%" Vector__XXX
 SG_ BMS_HV_Sts : 63|8@0+ (1,0) [0|255] "" Vector__XXX
BO_ 504 GW_EDS_OutPut_FR_0x1F8: 8 GW
 SG_ Checksum_0x1F8 : 7|8@0+ (1,0) [0|255] "" ESC
 SG_ Rolling_Counter_0x1F8 : 11|4@0+ (1,0) [0|15] "" ESC
 SG_ EDS_output_trq_FR : 47|16@0+ (1,-2000) [-2000|2000] "Nm" ESC
 SG_ EDS_output_trqValid_FR : 33|2@0+ (1,0) [0|1] "" ESC
 SG_ EDS_Spd_FR : 23|16@0+ (1,-20000) [-20000|20000] "rpm" ESC
 SG_ EDS_SpdValid_FR : 39|2@0+ (1,0) [0|1] "" ESC
 SG_ EDS_MotorDriveSts_FR : 35|2@0+ (1,0) [0|3] "" ESC
 SG_ EDS_Work_STS_FR : 15|4@0+ (1,0) [0|15] "" ESC
 SG_ EDS_powoff_req_FR : 37|2@0+ (1,0) [0|1] "" ESC
BO_ 889 GW_VCU_Sts2_0x379: 8 GW
 SG_ VCU_DriveCoolWaterPumpSts : 2|3@0+ (1,0) [0|5] "" Vector__XXX
 SG_ VCU_DriveCoolWaterDuty : 14|7@0+ (1,0) [0|100] "%" Vector__XXX
 SG_ VCU_BatteryWaterPumpSts_reserved : 30|3@0+ (1,0) [0|7] "" Vector__XXX
 SG_ VCU_BatteryWaterPumpDuty_reserved : 22|7@0+ (1,0) [0|100] "%" Vector__XXX
 SG_ VCU_DriveMode : 5|3@0+ (1,0) [0|7] "" Vector__XXX
 SG_ VCU_ActualGear : 26|3@0+ (1,0) [0|7] "" AVAS
 SG_ VCU_ACTGearValid : 27|1@0+ (1,0) [0|1] "" AVAS
 SG_ VCU_AccPedal1OutRange : 31|1@0+ (1,0) [0|1] "" Vector__XXX
 SG_ VCU_AccPedal2OutRange : 33|1@0+ (1,0) [0|1] "" Vector__XXX
 SG_ VCU_BrkPedal1OutRange : 35|1@0+ (1,0) [0|1] "" Vector__XXX
 SG_ VCU_BrkPedal2OutRange : 37|1@0+ (1,0) [0|1] "" Vector__XXX
 SG_ VCU_BrkPedalPct : 47|8@0+ (0.4,0) [0|100] "%" Vector__XXX
 SG_ VCU_AccPedalPosition : 55|8@0+ (0.4,0) [0|100] "%" Vector__XXX
 SG_ VCU_AccPedalPositionValid : 63|1@0+ (1,0) [0|1] "" Vector__XXX
 SG_ VCU_SocDisplay_EST : 62|7@0+ (1,0) [0|100] "%" Vector__XXX
 SG_ VCU_PowerLimit : 15|1@0+ (1,0) [0|1] "" Vector__XXX
 SG_ VCU_CruiseCtrlSts : 39|2@0+ (1,0) [0|3] "" ESC
 SG_ VCU_LowSOC_ERR : 23|1@0+ (1,0) [0|1] "" Vector__XXX
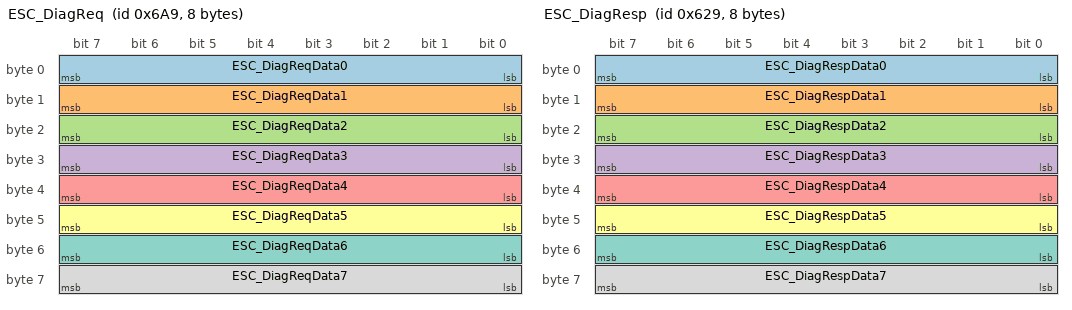
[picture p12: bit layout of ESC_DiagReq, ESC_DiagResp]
BO_ 1705 ESC_DiagReq: 8 GW
 SG_ ESC_DiagReqData0 : 7|8@0+ (1,0) [0|255] "" ESC
 SG_ ESC_DiagReqData1 : 15|8@0+ (1,0) [0|255] "" ESC
 SG_ ESC_DiagReqData2 : 23|8@0+ (1,0) [0|255] "" ESC
 SG_ ESC_DiagReqData3 : 31|8@0+ (1,0) [0|255] "" ESC
 SG_ ESC_DiagReqData4 : 39|8@0+ (1,0) [0|255] "" ESC
 SG_ ESC_DiagReqData5 : 47|8@0+ (1,0) [0|255] "" ESC
 SG_ ESC_DiagReqData6 : 55|8@0+ (1,0) [0|255] "" ESC
 SG_ ESC_DiagReqData7 : 63|8@0+ (1,0) [0|255] "" ESC
BO_ 1577 ESC_DiagResp: 8 ESC
 SG_ ESC_DiagRespData0 : 7|8@0+ (1,0) [0|255] "" GW
 SG_ ESC_DiagRespData1 : 15|8@0+ (1,0) [0|255] "" GW
 SG_ ESC_DiagRespData2 : 23|8@0+ (1,0) [0|255] "" GW
 SG_ ESC_DiagRespData3 : 31|8@0+ (1,0) [0|255] "" GW
 SG_ ESC_DiagRespData4 : 39|8@0+ (1,0) [0|255] "" GW
 SG_ ESC_DiagRespData5 : 47|8@0+ (1,0) [0|255] "" GW
 SG_ ESC_DiagRespData6 : 55|8@0+ (1,0) [0|255] "" GW
 SG_ ESC_DiagRespData7 : 63|8@0+ (1,0) [0|255] "" GW
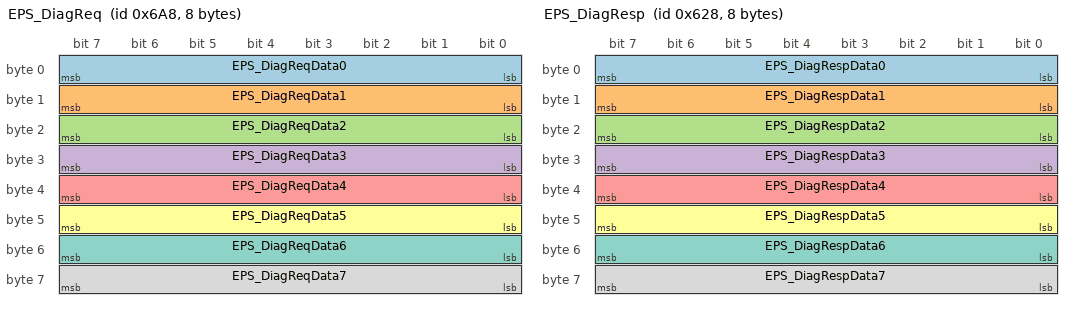
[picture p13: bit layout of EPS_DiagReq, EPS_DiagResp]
BO_ 1704 EPS_DiagReq: 8 GW
 SG_ EPS_DiagReqData0 : 7|8@0+ (1,0) [0|255] "" EPS
 SG_ EPS_DiagReqData1 : 15|8@0+ (1,0) [0|255] "" EPS
 SG_ EPS_DiagReqData2 : 23|8@0+ (1,0) [0|255] "" EPS
 SG_ EPS_DiagReqData3 : 31|8@0+ (1,0) [0|255] "" EPS
 SG_ EPS_DiagReqData4 : 39|8@0+ (1,0) [0|255] "" EPS
 SG_ EPS_DiagReqData5 : 47|8@0+ (1,0) [0|255] "" EPS
 SG_ EPS_DiagReqData6 : 55|8@0+ (1,0) [0|255] "" EPS
 SG_ EPS_DiagReqData7 : 63|8@0+ (1,0) [0|255] "" EPS
BO_ 1576 EPS_DiagResp: 8 EPS
 SG_ EPS_DiagRespData0 : 7|8@0+ (1,0) [0|255] "" GW
 SG_ EPS_DiagRespData1 : 15|8@0+ (1,0) [0|255] "" GW
 SG_ EPS_DiagRespData2 : 23|8@0+ (1,0) [0|255] "" GW
 SG_ EPS_DiagRespData3 : 31|8@0+ (1,0) [0|255] "" GW
 SG_ EPS_DiagRespData4 : 39|8@0+ (1,0) [0|255] "" GW
 SG_ EPS_DiagRespData5 : 47|8@0+ (1,0) [0|255] "" GW
 SG_ EPS_DiagRespData6 : 55|8@0+ (1,0) [0|255] "" GW
 SG_ EPS_DiagRespData7 : 63|8@0+ (1,0) [0|255] "" GW
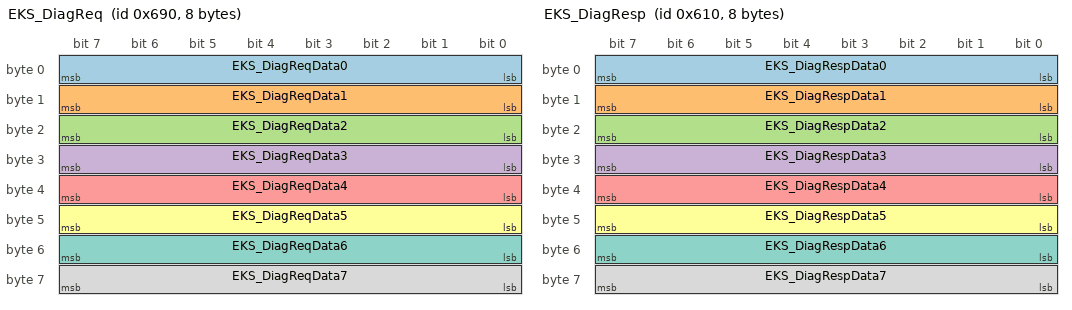
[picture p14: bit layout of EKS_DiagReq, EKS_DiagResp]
BO_ 1680 EKS_DiagReq: 8 GW
 SG_ EKS_DiagReqData0 : 7|8@0+ (1,0) [0|255] "" EKS
 SG_ EKS_DiagReqData1 : 15|8@0+ (1,0) [0|255] "" EKS
 SG_ EKS_DiagReqData2 : 23|8@0+ (1,0) [0|255] "" EKS
 SG_ EKS_DiagReqData3 : 31|8@0+ (1,0) [0|255] "" EKS
 SG_ EKS_DiagReqData4 : 39|8@0+ (1,0) [0|255] "" EKS
 SG_ EKS_DiagReqData5 : 47|8@0+ (1,0) [0|255] "" EKS
 SG_ EKS_DiagReqData6 : 55|8@0+ (1,0) [0|255] "" EKS
 SG_ EKS_DiagReqData7 : 63|8@0+ (1,0) [0|255] "" EKS
BO_ 1552 EKS_DiagResp: 8 EKS
 SG_ EKS_DiagRespData0 : 7|8@0+ (1,0) [0|255] "" GW
 SG_ EKS_DiagRespData1 : 15|8@0+ (1,0) [0|255] "" GW
 SG_ EKS_DiagRespData2 : 23|8@0+ (1,0) [0|255] "" GW
 SG_ EKS_DiagRespData3 : 31|8@0+ (1,0) [0|255] "" GW
 SG_ EKS_DiagRespData4 : 39|8@0+ (1,0) [0|255] "" GW
 SG_ EKS_DiagRespData5 : 47|8@0+ (1,0) [0|255] "" GW
 SG_ EKS_DiagRespData6 : 55|8@0+ (1,0) [0|255] "" GW
 SG_ EKS_DiagRespData7 : 63|8@0+ (1,0) [0|255] "" GW
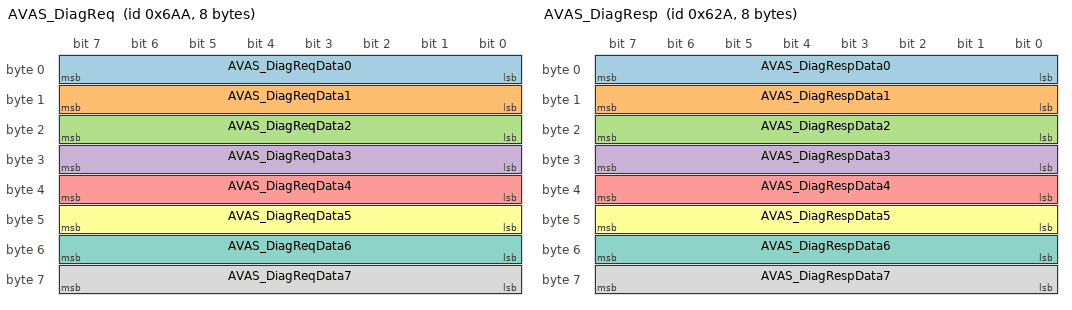
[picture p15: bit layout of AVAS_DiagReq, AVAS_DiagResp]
BO_ 1706 AVAS_DiagReq: 8 GW
 SG_ AVAS_DiagReqData0 : 7|8@0+ (1,0) [0|255] "" AVAS
 SG_ AVAS_DiagReqData1 : 15|8@0+ (1,0) [0|255] "" AVAS
 SG_ AVAS_DiagReqData2 : 23|8@0+ (1,0) [0|255] "" AVAS
 SG_ AVAS_DiagReqData3 : 31|8@0+ (1,0) [0|255] "" AVAS
 SG_ AVAS_DiagReqData4 : 39|8@0+ (1,0) [0|255] "" AVAS
 SG_ AVAS_DiagReqData5 : 47|8@0+ (1,0) [0|255] "" AVAS
 SG_ AVAS_DiagReqData6 : 55|8@0+ (1,0) [0|255] "" AVAS
 SG_ AVAS_DiagReqData7 : 63|8@0+ (1,0) [0|255] "" AVAS
BO_ 1578 AVAS_DiagResp: 8 AVAS
 SG_ AVAS_DiagRespData0 : 7|8@0+ (1,0) [0|255] "" GW
 SG_ AVAS_DiagRespData1 : 15|8@0+ (1,0) [0|255] "" GW
 SG_ AVAS_DiagRespData2 : 23|8@0+ (1,0) [0|255] "" GW
 SG_ AVAS_DiagRespData3 : 31|8@0+ (1,0) [0|255] "" GW
 SG_ AVAS_DiagRespData4 : 39|8@0+ (1,0) [0|255] "" GW
 SG_ AVAS_DiagRespData5 : 47|8@0+ (1,0) [0|255] "" GW
 SG_ AVAS_DiagRespData6 : 55|8@0+ (1,0) [0|255] "" GW
 SG_ AVAS_DiagRespData7 : 63|8@0+ (1,0) [0|255] "" GW
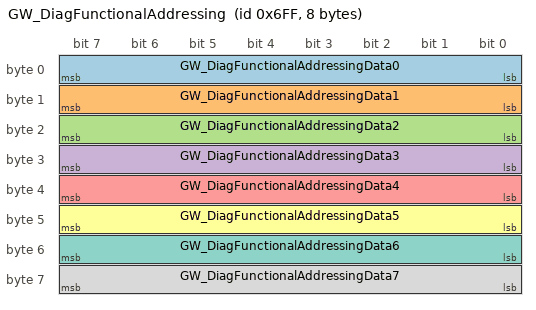
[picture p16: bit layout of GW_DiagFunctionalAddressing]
BO_ 1791 GW_DiagFunctionalAddressing: 8 GW
 SG_ GW_DiagFunctionalAddressingData0 : 7|8@0+ (1,0) [0|255] "" ESC,EPS,EKS,AVAS
 SG_ GW_DiagFunctionalAddressingData1 : 15|8@0+ (1,0) [0|255] "" ESC,EPS,EKS,AVAS
 SG_ GW_DiagFunctionalAddressingData2 : 23|8@0+ (1,0) [0|255] "" ESC,EPS,EKS,AVAS
 SG_ GW_DiagFunctionalAddressingData3 : 31|8@0+ (1,0) [0|255] "" ESC,EPS,EKS,AVAS
 SG_ GW_DiagFunctionalAddressingData4 : 39|8@0+ (1,0) [0|255] "" ESC,EPS,EKS,AVAS
 SG_ GW_DiagFunctionalAddressingData5 : 47|8@0+ (1,0) [0|255] "" ESC,EPS,EKS,AVAS
 SG_ GW_DiagFunctionalAddressingData6 : 55|8@0+ (1,0) [0|255] "" ESC,EPS,EKS,AVAS
 SG_ GW_DiagFunctionalAddressingData7 : 63|8@0+ (1,0) [0|255] "" ESC,EPS,EKS,AVAS
CM_ SG_ 306 Checksum_0x132 "check sum";
CM_ SG_ 306 RollingCounter_0x132 "Rolling counter";
CM_ SG_ 306 ESC_HSA_Control_Status "Indicate HSA function is active or not";
CM_ SG_ 306 ESC_HSA_Status_Fault "Detect the HAS Fault status";
CM_ SG_ 306 ESC_TcsDisableSts "Indicate the TCS function can use or not";
CM_ SG_ 306 ESC_TcsCtrlActv "Indicate TCS  function is active or not";
CM_ SG_ 306 ESC_TcsFlgFlt "Detect the TCS function fault status";
CM_ SG_ 306 ESC_EscDisableSts "Indicate the ESC function can use or not";
CM_ SG_ 306 ESC_EscCtrlActv "Indicate ESC  function is active or not";
CM_ SG_ 306 ESC_EscFlgFlt "Detect the ESC function fault status";
CM_ SG_ 306 ESC_HBAFlgFlt "Detect the HBA(Hydraulic Brake Assist) function status";
CM_ SG_ 306 ESC_HbaCtrlActv "Indicate HBA(Hydraulic Brake Assist)   function is active or not";
CM_ SG_ 306 ESC_SlopeGradeAngle "Vehicle slope,Uphill is negative (head is higher than tail), downhill is positive (tail is higher than head)";
CM_ SG_ 306 ESC_MasterCylinderPressure "Master cylinder pressure";
CM_ SG_ 322 Checksum_0x142 "check sum";
CM_ SG_ 322 RollingCounter_0x142 "Rolling counter";
CM_ SG_ 322 AbsDiagSessionLampReq_Reserved "ABS or ESC is currently in safety system diagnostic  session,(DVT mode) need cluster to turn on ESC/TCS, EBD, ABS fault lamp";
CM_ SG_ 322 ABS_AbsCtrlActv "ABS status(Indiacte ABS  function is active or not.When ABS intervention starts,it sets as 1)";
CM_ SG_ 322 ABS_EbdFlgFlt "The EBD system fault, The EBD warning lamp should be open,The signal will be set as  whenEBD is disable due to fault";
CM_ SG_ 322 ABS_AbsFlgFlt "The ABS system fault, The ABS warning lamp should be open,The signal will be set as whenABS is disable due to fault";
CM_ SG_ 322 ABS_ESS_Active "Emergency Stop Signaling Active,when emergency stop, this signal will set true";
CM_ SG_ 322 ABS_LowBrakeFluid "Detect the brake fluid level";
CM_ SG_ 818 Checksum_0x332 "check sum";
CM_ SG_ 818 RollingCounter_0x332 "Rolling counter";
CM_ SG_ 818 ABS_LFWhlSpdRaw "Current Raw wheel speed information of front left wheel.";
CM_ SG_ 818 ABS_LFWhlSpdRawValid "Current Raw wheel speed information valid flag of front left wheel.";
CM_ SG_ 818 ABS_RFWhlSpdRaw "Current Raw wheel speed information of front right wheel.";
CM_ SG_ 818 ABS_RFWhlSpdRawValid "Current Raw wheel speed information valid flag of front right wheel.";
CM_ SG_ 834 Checksum_0x342 "Check sum";
CM_ SG_ 834 RollingCounter_0x342 "Rolling Counter";
CM_ SG_ 834 ABS_LRWhlSpdRaw "Current Raw wheel speed information of rear left wheel.";
CM_ SG_ 834 ABS_LRWhlSpdRawValid "Current Raw wheel speed information valid flag of rear left wheel.";
CM_ SG_ 834 ABS_RRWhlSpdRaw "Current Raw wheel speed information of rear right wheel.,";
CM_ SG_ 834 ABS_RRWhlSpdRawValid "Current Raw wheel speed information valid flag of rear right wheel";
CM_ SG_ 834 ABS_VehSpd "Current Longitudinal Vehicle Speed";
CM_ SG_ 834 ABS_VehSpdValid "Speed Valid Flag";
CM_ SG_ 610 ABS_WssLFPulseCounter "left front wheel pluse counter";
CM_ SG_ 610 ABS_WssLFPulseCounterValid "left front wheel pluse counter valid";
CM_ SG_ 610 ABS_WssRFPulseCounter "right front wheel pluse counter";
CM_ SG_ 610 ABS_WssRFPulseCounterValid "right front wheel pluse counter valid";
CM_ SG_ 610 ABS_WssLRPulseCounter "left rear wheel pluse counter";
CM_ SG_ 610 ABS_WssLRPulseCounterValid "left rear wheel pluse counter valid";
CM_ SG_ 610 ABS_WssRRPulseCounter "right rear wheel pluse counter";
CM_ SG_ 610 ABS_WssRRPulseCounterValid "right rear wheel pluse counter valid";
CM_ SG_ 994 Checksum_0x3E2 "check sum";
CM_ SG_ 994 RollingCounter_0x3E2 "Rolling counter";
CM_ SG_ 994 ESC_LateralACC "Indicate lateral acceleration";
CM_ SG_ 994 ESC_LateralACC_Valid "Valid flag of lateral acceleration";
CM_ SG_ 994 ESC_LongitudeACC "Indicate longitude acceleration";
CM_ SG_ 994 ESC_LongitudeACC_Valid "Valid flag of longitude acceleration";
CM_ SG_ 994 ESC_VehDynYawRate "Indicate the yaw rate";
CM_ SG_ 994 ESC_VehDynYawRate_Valid "Valid flag of yaw rate";
CM_ SG_ 1010 Checksum_0x3F2 "check sum";
CM_ SG_ 1010 RollingCounter_0x3F2 "Rolling counter";
CM_ SG_ 1010 ESC_VehicleACC "vehicle acceleration";
CM_ SG_ 1010 ESC_VehicleACC_Valid "Valid flag of vehicle acceleration";
CM_ SG_ 866 Checksum_362 "check sum";
CM_ SG_ 866 RollingCounter_362 "Rolling counter";
CM_ SG_ 866 ESC_RegenDragCtrlStatus "Indicate RDC  function is active or not";
CM_ SG_ 866 ESC_RegenBrakeCtrlStatus "Indicate RBC  function is active or not";
CM_ SG_ 866 ESC_TorqReqMode "Indicate the torque request mode";
CM_ SG_ 866 ESC_TorqRequestVal "Regen torque request and TCS torque request(in motor torque domain)";
CM_ SG_ 1154 ESC_FLTirePressAlarm "Front left tire pressure alarm signal";
CM_ SG_ 1154 ESC_FRTirePressAlarm "Front right tire pressure alarm signal";
CM_ SG_ 1154 ESC_RLTirePressAlarm "Rear left tire pressure alarm signal";
CM_ SG_ 1154 ESC_RRTirePressAlarm "Rear right tire pressure alarm signal";
CM_ SG_ 1154 ESC_iTPMS_Err "Failure of tire pressure monitoring system";
CM_ SG_ 1154 ESC_iTPMS_WarnLampAct "The status of TPMS warning lamp";
CM_ SG_ 1154 ESC_iTPMSResetProhibit "Indicate whether calibration is allowed";
CM_ SG_ 1154 ESC_iTPMSResetSts "Tire pressure system reset status";
CM_ SG_ 382 Checksum_0x17E "Check sum";
CM_ SG_ 382 Rolling_counter_0x17E "Rolling Counter";
CM_ SG_ 382 SAS_SteerWheelAngle "The current angle of the steering wheel(Positive, to left; Negative, to right)";
CM_ SG_ 382 SAS_SteeringAngleValid "Effective signal for steering angle";
CM_ SG_ 382 SAS_SASStsSnsr "the flag of  SAS status Punch:Steering angle status";
CM_ SG_ 382 SAS_SteerWhlRotSpd "The current rotation speed of the steering wheel.";
CM_ SG_ 382 SAS_SteerWhlRotSpdStatus "The status of SteerWheel Rotation Speed valid";
CM_ SG_ 382 SAS_Calibrated "SAS calibration state of Steer Angle Sensor";
CM_ SG_ 382 SAS_SASFailure "Angle sensor disabled.";
CM_ SG_ 894 Checksum_0x37E "Check sum";
CM_ SG_ 894 Rolling_counter_0x37E "Rolling Counter";
CM_ SG_ 894 EPS_SteeringTorque "steering torque bosch(Positive, to left; Negative, to right)";
CM_ SG_ 894 EPS_TorqSensorStatus "Validation bit of torsion bar torque";
CM_ SG_ 894 EPS_EpsFailed "EPS failed bit";
CM_ SG_ 894 EPS_Mode "Electric steering mode";
CM_ SG_ 264 Checksum_0x108 "Check sum";
CM_ SG_ 264 RollingCounter_0x108 "Rolling Counter";
CM_ SG_ 264 EKS_DriveModeReq_reserved "The drive mode request";
CM_ SG_ 264 EKS_TargetGearReq "Target gear request";
CM_ SG_ 264 EKS_Fault "Fault statue";
CM_ SG_ 617 Checksum_0x269 "Check sum";
CM_ SG_ 617 RollingCounter_0x269 "Rolling counter";
CM_ SG_ 617 VCU_VehicleHVStatus "Vehicle High voltage Ready State";
CM_ SG_ 617 VCU_ActualGear "actual gear,Provide gear shift signal";
CM_ SG_ 617 VCU_ActualGearValid "Indicate the current gear position Valid";
CM_ SG_ 617 VCU_AccPedalPosition "Indicate the acceleraton pedal position";
CM_ SG_ 617 VCU_AccPedalPositionValid "Indicate the acceleration pedal position valid flag";
CM_ SG_ 617 VCU_TqReductionRqstResponse "Indicate the response for the RBS/TCS request torqueRBS/TCS";
CM_ SG_ 617 VCU_BrakePedalSts "Brake Pedal Sts";
CM_ SG_ 524 Checksum_0x20C "Checksum";
CM_ SG_ 524 Rolling_Counter_0x20C "Rolling_Counter";
CM_ SG_ 524 IPC_ODO "odograph";
CM_ SG_ 703 IPC_TripA "Set Trip A";
CM_ SG_ 703 IPC_AverageSpeedTripA "Average Speed of TripA";
CM_ SG_ 703 IPC_AverageConsumptionTripA "Average Consumption of TripA";
CM_ SG_ 703 IPC_ParkBrakeSts "Park Brake Status";
CM_ SG_ 703 IPC_VehSpd "Current Displayed Longitudinal Vehicle Speed";
CM_ SG_ 735 IPC_TireLearningReq_reserved "IPC request to ready to learning";
CM_ SG_ 735 IPC_TireResetReq "IPC request iTPMS reset";
CM_ SG_ 1087 IPC_Sec "Represents the current second.60 - 63 = Invalid";
CM_ SG_ 1087 IPC_Min "Represents the current minute. 60 - 63 = Invalid";
CM_ SG_ 1087 IPC_Hour "Represents the current hour, 24 - 30 = not used";
CM_ SG_ 1087 IPC_Day "Represents the current dayInvalid value = 0";
CM_ SG_ 1087 IPC_Month "Represents the current month.0, 13 to 15 = Invalid";
CM_ SG_ 1087 IPC_Year "Represents the current year.";
CM_ SG_ 1087 IPC_SelfCheckStatus "Power on self check status";
CM_ SG_ 814 CCU_ExternalTemperature "External Temperature";
CM_ SG_ 814 CCU_ExternalTemperatureFailSts "External Temperature Fail Sts";
CM_ SG_ 967 MHU_VehsSpd_Warn "MHU  To Configure  OverSpeed Threshold";
CM_ SG_ 967 MHU_SET_Volume "MHU SET IPC volume";
CM_ SG_ 967 MHU_St_DimmingIPC "MHU  Background lump level setting to IPC";
CM_ SG_ 1027 Checksum_0x403 "Checksum";
CM_ SG_ 1027 Rolling_Counter_0x403 "Rolling_Counter";
CM_ SG_ 1027 MHU_SET_TCS_OnOff "Change TCS mode ON/OFF";
CM_ SG_ 1027 MHU_SET_DrivingModeSwitch "Change vehicle driving mode";
CM_ SG_ 1027 MHU_SET_RegenLevel "Set power regenerative level";
CM_ SG_ 1027 MHU_VCU_CreepDisable_stt "Request for VCU to disable creep function";
CM_ SG_ 1027 MHU_ChargeSetTargetSOC "Request for VCU to set target HV SOC";
CM_ SG_ 1027 MHU_HVACTurnON "Turning ON HVAC remotely";
CM_ SG_ 1027 MHU_ChargeScheduleSet "Request for VCU to enable/disable Charging Scheduling";
CM_ SG_ 1027 MHU_ChargingRequest "Request for VCU to ON/OFF Charging when schedule is reached";
CM_ SG_ 1027 MHU_ValetMode_Activation "Activate Valet mode from MHU";
CM_ SG_ 1027 MHU_ValetMode_MaxSpeed "Setting of maximum allowable in valet mode";
CM_ SG_ 848 BCM_STAT_DoorAjarDriver "Ajar Door Driver Status";
CM_ SG_ 848 BCM_PosLmpSts "Position light output Status";
CM_ SG_ 266 Checksum_0x10a "Checksum";
CM_ SG_ 266 Rolling_Counter_0x10a "Rolling Counter";
CM_ SG_ 266 BCM_LVTop_up "LV  battery top up requice signal";
CM_ SG_ 266 Ubatt_Reserved "Battery Voltage(UBatt to be received by all modules,Required for DTC snapshots)";
CM_ SG_ 274 Checksum_0x112 "Checksum";
CM_ SG_ 274 Rolling_Counter_0x112 "Rolling_Counter";
CM_ SG_ 274 STAT_Terminal "Represent the status of physical terminal(STAT_Terminal to be received by all modules,Required for DTC snapshots and for FOTA)";
CM_ SG_ 274 STAT_CL30s_L_Reserved "Status Clamp 30s Logical ON/OFF";
CM_ SG_ 133 Checksum_0x85 "Check sum";
CM_ SG_ 133 RollingCounter_0x85 "Rolling counter";
CM_ SG_ 133 ACM_Crash_Sts "Crash status";
CM_ SG_ 133 ACM_Airbag_Deployment_Status "Signal to indicate if airbag/pretensioner/pyrofuse is deployed";
CM_ SG_ 133 ACM_Crash_Intensity "Indicate crash intensity level";
CM_ SG_ 133 ACM_Front_Crash "Output information for direction of crash";
CM_ SG_ 133 ACM_DriverSide_Crash "Output information for direction of crash";
CM_ SG_ 133 ACM_PassSide_Crash "Output information for direction of crash";
CM_ SG_ 133 ACM_Rear_Crash "Output information for direction of crash";
CM_ SG_ 133 ACM_Rollover_Crash "Output information for direction of crash";
CM_ SG_ 897 Checksum_0x381 "Checksum";
CM_ SG_ 897 Rolling_Counter_0x381 "Rolling Counter";
CM_ SG_ 897 ACM_Seat_Occupancy_Passenger "Signal to indicate status of occupancy";
CM_ SG_ 897 ACM_Seat_Occupancy_2nd_Row_Dri_reserved "Signal to indicate status of occupancy";
CM_ SG_ 897 ACM_Seat_Occupancy_2nd_Row_Pas_reserved "Signal to indicate status of occupancy";
CM_ SG_ 897 ACM_Seat_Occupancy_2nd_Row_Mid_reserved "Signal to indicate status of occupancy";
CM_ SG_ 897 ACM_Seat_Belt_Status_Passenger "Seatbelt status for seatbelt reminder function";
CM_ SG_ 897 ACM_Seat_Belt_Status_Driver "Seatbelt status for seatbelt reminder function";
CM_ SG_ 897 ACM_Seat_Belt_Status_2nd_Row_Dri_reserved "Seatbelt status for seatbelt reminder function";
CM_ SG_ 897 ACM_Seat_Belt_Status_2nd_Row_Mid_reserved "Seatbelt status for seatbelt reminder function";
CM_ SG_ 897 ACM_Seat_Belt_Status_2nd_Row_Pas_reserved "Seatbelt status for seatbelt reminder function";
CM_ SG_ 897 ACM_Seat_Belt_Status_3rd_Row_Dri_reserved "Seatbelt status for seatbelt reminder function";
CM_ SG_ 897 ACM_Seat_Belt_Status_3rd_Row_Pas_reserved "Seatbelt status for seatbelt reminder function";
CM_ SG_ 533 Checksum_0x215 "Checksum";
CM_ SG_ 533 Rolling_Counter_0x215 "Rolling Counter";
CM_ SG_ 533 BMS_SOE "BMS State Of Enegy";
CM_ SG_ 533 BMS_HWCrash_Sts "Battery Pack Hardware Crash signal Status";
CM_ SG_ 533 BMS_HVIL_STS "The HVIL state of BMS";
CM_ SG_ 533 BMS_IGN_Sts "the ignition signal status (on/off)";
CM_ SG_ 533 BMS_Sys_STS "BMS_Status(Self-test after BMS wake-up)";
CM_ SG_ 533 BMS_HVOnOff_STS "BMS High Voltage Status(BMS_HVOnOff_STS to be received by all modules,Used as a flash programming pre-condition (replacement for engine running)";
CM_ SG_ 533 BMS_Balance_STS "BMS Balance Status";
CM_ SG_ 533 BMS_SocActual_EST "Actual SOC";
CM_ SG_ 533 BMS_BatBalance_ERR "Battery Balance Error indicates Balancing switch is short or open";
CM_ SG_ 533 BMS_ISU_Status "Insulation status";
CM_ SG_ 533 BMS_ERR_LEV "BMS requesting VCU to operate at the limited operating strategy (LOS)";
CM_ SG_ 533 BMS_SOH "BMS State Of Health";
CM_ SG_ 533 BMS_HV_Sts "BMS High Voltage Status";
CM_ SG_ 504 Checksum_0x1F8 "Check sum";
CM_ SG_ 504 Rolling_Counter_0x1F8 "Rolling counter";
CM_ SG_ 504 EDS_output_trq_FR "Actual output torque of current EDS";
CM_ SG_ 504 EDS_output_trqValid_FR "Indicate the valid flag of current motor torque";
CM_ SG_ 504 EDS_Spd_FR "current motor speed";
CM_ SG_ 504 EDS_SpdValid_FR "Indicate the valid flag of current motor speed";
CM_ SG_ 504 EDS_MotorDriveSts_FR "The drive state of EDS";
CM_ SG_ 504 EDS_Work_STS_FR "EDS Work status";
CM_ SG_ 504 EDS_powoff_req_FR "If there is a serious failure in the running process of EDS, the high voltage of VCU will be requested";
CM_ SG_ 889 VCU_DriveCoolWaterPumpSts "Motor electronic pump state";
CM_ SG_ 889 VCU_DriveCoolWaterDuty "Motor electronic pump occupancy";
CM_ SG_ 889 VCU_BatteryWaterPumpSts_reserved "Battery electronic pump state";
CM_ SG_ 889 VCU_BatteryWaterPumpDuty_reserved "Battery electronic pump occupancy";
CM_ SG_ 889 VCU_DriveMode "Vehicle drive mode";
CM_ SG_ 889 VCU_ActualGear "actual gear,Provide gear shift signal";
CM_ SG_ 889 VCU_ACTGearValid "Indicate the current gear position";
CM_ SG_ 889 VCU_AccPedal1OutRange "The state of accelerator pedal1";
CM_ SG_ 889 VCU_AccPedal2OutRange "The state of accelerator pedal2";
CM_ SG_ 889 VCU_BrkPedal1OutRange "The synchronization state of brake pedal1";
CM_ SG_ 889 VCU_BrkPedal2OutRange "The state of barke pedal2";
CM_ SG_ 889 VCU_BrkPedalPct "The percent of brake pedal";
CM_ SG_ 889 VCU_AccPedalPosition "Indicate the acceleraton pedal position";
CM_ SG_ 889 VCU_AccPedalPositionValid "Indicate the acceleration pedal position valid flag";
CM_ SG_ 889 VCU_SocDisplay_EST "Battery SOC";
CM_ SG_ 889 VCU_PowerLimit "Vehicle power limit";
CM_ SG_ 889 VCU_CruiseCtrlSts "Cruise state";
CM_ SG_ 889 VCU_LowSOC_ERR "Battery SOC low";
CM_ SG_ 1705 ESC_DiagReqData0 "Data0";
CM_ SG_ 1705 ESC_DiagReqData1 "Data1";
CM_ SG_ 1705 ESC_DiagReqData2 "Data2";
CM_ SG_ 1705 ESC_DiagReqData3 "Data3";
CM_ SG_ 1705 ESC_DiagReqData4 "Data4";
CM_ SG_ 1705 ESC_DiagReqData5 "Data5";
CM_ SG_ 1705 ESC_DiagReqData6 "Data6";
CM_ SG_ 1705 ESC_DiagReqData7 "Data7";
CM_ SG_ 1577 ESC_DiagRespData0 "Data0";
CM_ SG_ 1577 ESC_DiagRespData1 "Data1";
CM_ SG_ 1577 ESC_DiagRespData2 "Data2";
CM_ SG_ 1577 ESC_DiagRespData3 "Data3";
CM_ SG_ 1577 ESC_DiagRespData4 "Data4";
CM_ SG_ 1577 ESC_DiagRespData5 "Data5";
CM_ SG_ 1577 ESC_DiagRespData6 "Data6";
CM_ SG_ 1577 ESC_DiagRespData7 "Data7";
CM_ SG_ 1704 EPS_DiagReqData0 "Data0";
CM_ SG_ 1704 EPS_DiagReqData1 "Data1";
CM_ SG_ 1704 EPS_DiagReqData2 "Data2";
CM_ SG_ 1704 EPS_DiagReqData3 "Data3";
CM_ SG_ 1704 EPS_DiagReqData4 "Data4";
CM_ SG_ 1704 EPS_DiagReqData5 "Data5";
CM_ SG_ 1704 EPS_DiagReqData6 "Data6";
CM_ SG_ 1704 EPS_DiagReqData7 "Data7";
CM_ SG_ 1576 EPS_DiagRespData0 "Data0";
CM_ SG_ 1576 EPS_DiagRespData1 "Data1";
CM_ SG_ 1576 EPS_DiagRespData2 "Data2";
CM_ SG_ 1576 EPS_DiagRespData3 "Data3";
CM_ SG_ 1576 EPS_DiagRespData4 "Data4";
CM_ SG_ 1576 EPS_DiagRespData5 "Data5";
CM_ SG_ 1576 EPS_DiagRespData6 "Data6";
CM_ SG_ 1576 EPS_DiagRespData7 "Data7";
CM_ SG_ 1680 EKS_DiagReqData0 "Data0";
CM_ SG_ 1680 EKS_DiagReqData1 "Data1";
CM_ SG_ 1680 EKS_DiagReqData2 "Data2";
CM_ SG_ 1680 EKS_DiagReqData3 "Data3";
CM_ SG_ 1680 EKS_DiagReqData4 "Data4";
CM_ SG_ 1680 EKS_DiagReqData5 "Data5";
CM_ SG_ 1680 EKS_DiagReqData6 "Data6";
CM_ SG_ 1680 EKS_DiagReqData7 "Data7";
CM_ SG_ 1552 EKS_DiagRespData0 "Data0";
CM_ SG_ 1552 EKS_DiagRespData1 "Data1";
CM_ SG_ 1552 EKS_DiagRespData2 "Data2";
CM_ SG_ 1552 EKS_DiagRespData3 "Data3";
CM_ SG_ 1552 EKS_DiagRespData4 "Data4";
CM_ SG_ 1552 EKS_DiagRespData5 "Data5";
CM_ SG_ 1552 EKS_DiagRespData6 "Data6";
CM_ SG_ 1552 EKS_DiagRespData7 "Data7";
CM_ SG_ 1706 AVAS_DiagReqData0 "Data0";
CM_ SG_ 1706 AVAS_DiagReqData1 "Data1";
CM_ SG_ 1706 AVAS_DiagReqData2 "Data2";
CM_ SG_ 1706 AVAS_DiagReqData3 "Data3";
CM_ SG_ 1706 AVAS_DiagReqData4 "Data4";
CM_ SG_ 1706 AVAS_DiagReqData5 "Data5";
CM_ SG_ 1706 AVAS_DiagReqData6 "Data6";
CM_ SG_ 1706 AVAS_DiagReqData7 "Data7";
CM_ SG_ 1578 AVAS_DiagRespData0 "Data0";
CM_ SG_ 1578 AVAS_DiagRespData1 "Data1";
CM_ SG_ 1578 AVAS_DiagRespData2 "Data2";
CM_ SG_ 1578 AVAS_DiagRespData3 "Data3";
CM_ SG_ 1578 AVAS_DiagRespData4 "Data4";
CM_ SG_ 1578 AVAS_DiagRespData5 "Data5";
CM_ SG_ 1578 AVAS_DiagRespData6 "Data6";
CM_ SG_ 1578 AVAS_DiagRespData7 "Data7";
CM_ SG_ 1791 GW_DiagFunctionalAddressingData0 "Data0";
CM_ SG_ 1791 GW_DiagFunctionalAddressingData1 "Data1";
CM_ SG_ 1791 GW_DiagFunctionalAddressingData2 "Data2";
CM_ SG_ 1791 GW_DiagFunctionalAddressingData3 "Data3";
CM_ SG_ 1791 GW_DiagFunctionalAddressingData4 "Data4";
CM_ SG_ 1791 GW_DiagFunctionalAddressingData5 "Data5";
CM_ SG_ 1791 GW_DiagFunctionalAddressingData6 "Data6";
CM_ SG_ 1791 GW_DiagFunctionalAddressingData7 "Data7";
BA_DEF_ BO_ "DiagRequest" ENUM "No","Yes";
BA_DEF_ BO_ "DiagResponse" ENUM "No","Yes";
BA_DEF_ BO_ "DiagState" ENUM "No","Yes";
BA_DEF_ BO_ "GenMsgCycleTime" INT 0 65535;
BA_DEF_ BO_ "GenMsgCycleTimeFast" INT 0 65535;
BA_DEF_ BO_ "GenMsgDelayTime" INT 0 65535;
BA_DEF_ BO_ "GenMsgILSupport" ENUM "No","Yes";
BA_DEF_ BO_ "GenMsgNrOfRepetition" INT 0 65535;
BA_DEF_ BO_ "GenMsgSendType" ENUM  "Cycle","Event","IfActive","CE","CA";
BA_DEF_ SG_ "GenSigSendType" ENUM  "Cycle","OnWrite","OnWriteWithRepetition","OnChange","OnChangeWithRepetition","IfActive","IfActiveWithRepetition";
BA_DEF_ SG_ "GenSigStartValue" INT 0 2147483647;
BA_DEF_ SG_ "GenSigInvalidValue" INT 0 2147483647;
BA_DEF_ SG_ "GenSigInactiveValue" INT 0 2147483647;
BA_DEF_ BU_ "ILUsed" ENUM  "No","Yes";
BA_DEF_ BU_ "NmAsrCanMsgReducedTime" INT 320 640;
BA_DEF_  "Baudrate" INT 0 1000000;
BA_DEF_  "BusType" STRING;
BA_DEF_  "Manufacturer" STRING;
BA_DEF_  "NmAsrBaseAddress" HEX 0 2047;
BA_DEF_  "NmAsrCanMsgCycleTime" INT 0 65535;
BA_DEF_  "NmAsrMessageCount" INT 1 256;
BA_DEF_  "NmAsrRepeatMessageTime" INT 0 65535;
BA_DEF_  "NmAsrTimeoutTime" INT 0 65535;
BA_DEF_  "NmAsrWaitBusSleepTime" INT 0 65535;
BA_DEF_  "NmType" STRING;
BA_DEF_DEF_ "Baudrate" 500000;
BA_DEF_DEF_ "BusType" "CAN";
BA_DEF_DEF_ "DiagRequest" "No";
BA_DEF_DEF_ "DiagResponse" "No";
BA_DEF_DEF_ "DiagState" "No";
BA_DEF_DEF_ "GenMsgCycleTime" 0;
BA_DEF_DEF_ "GenMsgCycleTimeFast" 0;
BA_DEF_DEF_ "GenMsgDelayTime" 0;
BA_DEF_DEF_ "GenMsgILSupport" "Yes";
BA_DEF_DEF_ "GenMsgNrOfRepetition" 0;
BA_DEF_DEF_ "GenMsgSendType" "NoMsgSendType";
BA_DEF_DEF_ "GenSigSendType" "NoSigSendType";
BA_DEF_DEF_ "GenSigStartValue" 0;
BA_DEF_DEF_  "GenSigInvalidValue" 0;
BA_DEF_DEF_ "GenSigInactiveValue" 0;
BA_DEF_DEF_ "ILUsed" "Yes";
BA_DEF_DEF_ "Manufacturer" "Launch";
BA_DEF_DEF_ "NmAsrBaseAddress" 1280;
BA_DEF_DEF_ "NmAsrCanMsgCycleTime" 640;
BA_DEF_DEF_ "NmAsrCanMsgReducedTime" 320;
BA_DEF_DEF_ "NmAsrMessageCount" 128;
BA_DEF_DEF_ "NmAsrRepeatMessageTime" 3200;
BA_DEF_DEF_ "NmAsrTimeoutTime" 2000;
BA_DEF_DEF_ "NmAsrWaitBusSleepTime" 1500;
BA_DEF_DEF_ "NmType" "NmAsr";

BA_ "GenMsgSendType" BO_ 306 0;
BA_ "GenMsgCycleTime" BO_ 306 20;
BA_ "GenMsgSendType" BO_ 322 0;
BA_ "GenMsgCycleTime" BO_ 322 20;
BA_ "GenMsgSendType" BO_ 818 0;
BA_ "GenMsgCycleTime" BO_ 818 10;
BA_ "GenMsgSendType" BO_ 834 0;
BA_ "GenMsgCycleTime" BO_ 834 10;
BA_ "GenMsgSendType" BO_ 610 0;
BA_ "GenMsgCycleTime" BO_ 610 10;
BA_ "GenMsgSendType" BO_ 994 0;
BA_ "GenMsgCycleTime" BO_ 994 20;
BA_ "GenMsgSendType" BO_ 1010 0;
BA_ "GenMsgCycleTime" BO_ 1010 20;
BA_ "GenMsgSendType" BO_ 866 0;
BA_ "GenMsgCycleTime" BO_ 866 20;
BA_ "GenMsgSendType" BO_ 1154 0;
BA_ "GenMsgCycleTime" BO_ 1154 50;
BA_ "GenMsgSendType" BO_ 382 0;
BA_ "GenMsgCycleTime" BO_ 382 10;
BA_ "GenMsgSendType" BO_ 894 0;
BA_ "GenMsgCycleTime" BO_ 894 20;
BA_ "GenMsgSendType" BO_ 264 0;
BA_ "GenMsgCycleTime" BO_ 264 50;
BA_ "GenMsgSendType" BO_ 617 0;
BA_ "GenMsgCycleTime" BO_ 617 20;
BA_ "GenMsgSendType" BO_ 524 0;
BA_ "GenMsgCycleTime" BO_ 524 100;
BA_ "GenMsgSendType" BO_ 703 0;
BA_ "GenMsgCycleTime" BO_ 703 50;
BA_ "GenMsgSendType" BO_ 735 1;
BA_ "GenMsgNrOfRepetition" BO_ 735 5;
BA_ "GenMsgCycleTimeFast" BO_ 735 50;
BA_ "GenMsgSendType" BO_ 1087 0;
BA_ "GenMsgCycleTime" BO_ 1087 1000;
BA_ "GenMsgSendType" BO_ 814 0;
BA_ "GenMsgCycleTime" BO_ 814 50;
BA_ "GenMsgSendType" BO_ 967 0;
BA_ "GenMsgNrOfRepetition" BO_ 967 5;
BA_ "GenMsgDelayTime" BO_ 967 30;
BA_ "GenMsgCycleTimeFast" BO_ 967 50;
BA_ "GenMsgCycleTime" BO_ 967 100;
BA_ "GenMsgSendType" BO_ 1027 3;
BA_ "GenMsgNrOfRepetition" BO_ 1027 5;
BA_ "GenMsgCycleTimeFast" BO_ 1027 20;
BA_ "GenMsgCycleTime" BO_ 1027 100;
BA_ "GenMsgSendType" BO_ 848 0;
BA_ "GenMsgCycleTime" BO_ 848 50;
BA_ "GenMsgSendType" BO_ 266 0;
BA_ "GenMsgCycleTime" BO_ 266 100;
BA_ "GenMsgSendType" BO_ 274 0;
BA_ "GenMsgCycleTime" BO_ 274 100;
BA_ "GenMsgSendType" BO_ 133 0;
BA_ "GenMsgCycleTime" BO_ 133 20;
BA_ "GenMsgSendType" BO_ 897 0;
BA_ "GenMsgCycleTime" BO_ 897 200;
BA_ "GenMsgSendType" BO_ 533 0;
BA_ "GenMsgCycleTime" BO_ 533 50;
BA_ "GenMsgSendType" BO_ 504 0;
BA_ "GenMsgCycleTime" BO_ 504 10;
BA_ "GenMsgSendType" BO_ 889 0;
BA_ "GenMsgCycleTime" BO_ 889 50;
BA_ "GenMsgSendType" BO_ 1705 1;
BA_ "DiagRequest" BO_ 1705 1;
BA_ "GenMsgSendType" BO_ 1577 1;
BA_ "DiagResponse" BO_ 1577 1;
BA_ "GenMsgSendType" BO_ 1704 1;
BA_ "DiagRequest" BO_ 1704 1;
BA_ "GenMsgSendType" BO_ 1576 1;
BA_ "DiagResponse" BO_ 1576 1;
BA_ "GenMsgSendType" BO_ 1680 1;
BA_ "DiagRequest" BO_ 1680 1;
BA_ "GenMsgSendType" BO_ 1552 1;
BA_ "DiagResponse" BO_ 1552 1;
BA_ "GenMsgSendType" BO_ 1706 1;
BA_ "DiagRequest" BO_ 1706 1;
BA_ "GenMsgSendType" BO_ 1578 1;
BA_ "DiagResponse" BO_ 1578 1;
BA_ "GenMsgSendType" BO_ 1791 1;
BA_ "DiagState" BO_ 1791 1;
BA_ "GenSigSendType" SG_ 306 Checksum_0x132 0;
BA_ "GenSigSendType" SG_ 306 RollingCounter_0x132 0;
BA_ "GenSigInvalidValue" SG_ 306 RollingCounter_0x132 15;
BA_ "GenSigSendType" SG_ 306 ESC_HSA_Control_Status 0;
BA_ "GenSigSendType" SG_ 306 ESC_HSA_Status_Fault 0;
BA_ "GenSigSendType" SG_ 306 ESC_TcsDisableSts 0;
BA_ "GenSigInvalidValue" SG_ 306 ESC_TcsDisableSts 3;
BA_ "GenSigSendType" SG_ 306 ESC_TcsCtrlActv 0;
BA_ "GenSigSendType" SG_ 306 ESC_TcsFlgFlt 0;
BA_ "GenSigSendType" SG_ 306 ESC_EscDisableSts 0;
BA_ "GenSigSendType" SG_ 306 ESC_EscCtrlActv 0;
BA_ "GenSigSendType" SG_ 306 ESC_EscFlgFlt 0;
BA_ "GenSigSendType" SG_ 306 ESC_HBAFlgFlt 0;
BA_ "GenSigSendType" SG_ 306 ESC_HbaCtrlActv 0;
BA_ "GenSigSendType" SG_ 306 ESC_SlopeGradeAngle 0;
BA_ "GenSigInvalidValue" SG_ 306 ESC_SlopeGradeAngle 255;
BA_ "GenSigSendType" SG_ 306 ESC_MasterCylinderPressure 0;
BA_ "GenSigInvalidValue" SG_ 306 ESC_MasterCylinderPressure 4095;
BA_ "GenSigStartValue" SG_ 306 ESC_MasterCylinderPressure 1000;
BA_ "GenSigSendType" SG_ 322 Checksum_0x142 0;
BA_ "GenSigSendType" SG_ 322 RollingCounter_0x142 0;
BA_ "GenSigInvalidValue" SG_ 322 RollingCounter_0x142 15;
BA_ "GenSigSendType" SG_ 322 AbsDiagSessionLampReq_Reserved 0;
BA_ "GenSigSendType" SG_ 322 ABS_AbsCtrlActv 0;
BA_ "GenSigSendType" SG_ 322 ABS_EbdFlgFlt 0;
BA_ "GenSigSendType" SG_ 322 ABS_AbsFlgFlt 0;
BA_ "GenSigSendType" SG_ 322 ABS_ESS_Active 0;
BA_ "GenSigSendType" SG_ 322 ABS_LowBrakeFluid 0;
BA_ "GenSigSendType" SG_ 818 Checksum_0x332 0;
BA_ "GenSigSendType" SG_ 818 RollingCounter_0x332 0;
BA_ "GenSigInvalidValue" SG_ 818 RollingCounter_0x332 15;
BA_ "GenSigSendType" SG_ 818 ABS_LFWhlSpdRaw 0;
BA_ "GenSigInvalidValue" SG_ 818 ABS_LFWhlSpdRaw 32767;
BA_ "GenSigSendType" SG_ 818 ABS_LFWhlSpdRawValid 0;
BA_ "GenSigSendType" SG_ 818 ABS_RFWhlSpdRaw 0;
BA_ "GenSigInvalidValue" SG_ 818 ABS_RFWhlSpdRaw 32767;
BA_ "GenSigSendType" SG_ 818 ABS_RFWhlSpdRawValid 0;
BA_ "GenSigSendType" SG_ 834 Checksum_0x342 0;
BA_ "GenSigSendType" SG_ 834 RollingCounter_0x342 0;
BA_ "GenSigInvalidValue" SG_ 834 RollingCounter_0x342 15;
BA_ "GenSigSendType" SG_ 834 ABS_LRWhlSpdRaw 0;
BA_ "GenSigInvalidValue" SG_ 834 ABS_LRWhlSpdRaw 32767;
BA_ "GenSigSendType" SG_ 834 ABS_LRWhlSpdRawValid 0;
BA_ "GenSigSendType" SG_ 834 ABS_RRWhlSpdRaw 0;
BA_ "GenSigInvalidValue" SG_ 834 ABS_RRWhlSpdRaw 32767;
BA_ "GenSigSendType" SG_ 834 ABS_RRWhlSpdRawValid 0;
BA_ "GenSigSendType" SG_ 834 ABS_VehSpd 0;
BA_ "GenSigInvalidValue" SG_ 834 ABS_VehSpd 32767;
BA_ "GenSigSendType" SG_ 834 ABS_VehSpdValid 0;
BA_ "GenSigSendType" SG_ 610 ABS_WssLFPulseCounter 0;
BA_ "GenSigInvalidValue" SG_ 610 ABS_WssLFPulseCounter 32767;
BA_ "GenSigSendType" SG_ 610 ABS_WssLFPulseCounterValid 0;
BA_ "GenSigSendType" SG_ 610 ABS_WssRFPulseCounter 0;
BA_ "GenSigInvalidValue" SG_ 610 ABS_WssRFPulseCounter 32767;
BA_ "GenSigSendType" SG_ 610 ABS_WssRFPulseCounterValid 0;
BA_ "GenSigSendType" SG_ 610 ABS_WssLRPulseCounter 0;
BA_ "GenSigInvalidValue" SG_ 610 ABS_WssLRPulseCounter 32767;
BA_ "GenSigSendType" SG_ 610 ABS_WssLRPulseCounterValid 0;
BA_ "GenSigSendType" SG_ 610 ABS_WssRRPulseCounter 0;
BA_ "GenSigInvalidValue" SG_ 610 ABS_WssRRPulseCounter 32767;
BA_ "GenSigSendType" SG_ 610 ABS_WssRRPulseCounterValid 0;
BA_ "GenSigSendType" SG_ 994 Checksum_0x3E2 0;
BA_ "GenSigSendType" SG_ 994 RollingCounter_0x3E2 0;
BA_ "GenSigInvalidValue" SG_ 994 RollingCounter_0x3E2 15;
BA_ "GenSigSendType" SG_ 994 ESC_LateralACC 0;
BA_ "GenSigInvalidValue" SG_ 994 ESC_LateralACC 255;
BA_ "GenSigStartValue" SG_ 994 ESC_LateralACC 127;
BA_ "GenSigSendType" SG_ 994 ESC_LateralACC_Valid 0;
BA_ "GenSigSendType" SG_ 994 ESC_LongitudeACC 0;
BA_ "GenSigInvalidValue" SG_ 994 ESC_LongitudeACC 1023;
BA_ "GenSigStartValue" SG_ 994 ESC_LongitudeACC 511;
BA_ "GenSigSendType" SG_ 994 ESC_LongitudeACC_Valid 0;
BA_ "GenSigSendType" SG_ 994 ESC_VehDynYawRate 0;
BA_ "GenSigInvalidValue" SG_ 994 ESC_VehDynYawRate 16383;
BA_ "GenSigSendType" SG_ 994 ESC_VehDynYawRate_Valid 0;
BA_ "GenSigSendType" SG_ 1010 Checksum_0x3F2 0;
BA_ "GenSigSendType" SG_ 1010 RollingCounter_0x3F2 0;
BA_ "GenSigInvalidValue" SG_ 1010 RollingCounter_0x3F2 15;
BA_ "GenSigSendType" SG_ 1010 ESC_VehicleACC 0;
BA_ "GenSigInvalidValue" SG_ 1010 ESC_VehicleACC 1023;
BA_ "GenSigStartValue" SG_ 1010 ESC_VehicleACC 511;
BA_ "GenSigSendType" SG_ 1010 ESC_VehicleACC_Valid 0;
BA_ "GenSigSendType" SG_ 866 Checksum_362 0;
BA_ "GenSigSendType" SG_ 866 RollingCounter_362 0;
BA_ "GenSigInvalidValue" SG_ 866 RollingCounter_362 15;
BA_ "GenSigSendType" SG_ 866 ESC_RegenDragCtrlStatus 0;
BA_ "GenSigSendType" SG_ 866 ESC_RegenBrakeCtrlStatus 0;
BA_ "GenSigSendType" SG_ 866 ESC_TorqReqMode 0;
BA_ "GenSigSendType" SG_ 866 ESC_TorqRequestVal 0;
BA_ "GenSigInvalidValue" SG_ 866 ESC_TorqRequestVal 65535;
BA_ "GenSigSendType" SG_ 1154 ESC_FLTirePressAlarm 0;
BA_ "GenSigInvalidValue" SG_ 1154 ESC_FLTirePressAlarm 1;
BA_ "GenSigSendType" SG_ 1154 ESC_FRTirePressAlarm 0;
BA_ "GenSigInvalidValue" SG_ 1154 ESC_FRTirePressAlarm 1;
BA_ "GenSigSendType" SG_ 1154 ESC_RLTirePressAlarm 0;
BA_ "GenSigInvalidValue" SG_ 1154 ESC_RLTirePressAlarm 1;
BA_ "GenSigSendType" SG_ 1154 ESC_RRTirePressAlarm 0;
BA_ "GenSigInvalidValue" SG_ 1154 ESC_RRTirePressAlarm 1;
BA_ "GenSigSendType" SG_ 1154 ESC_iTPMS_Err 0;
BA_ "GenSigInvalidValue" SG_ 1154 ESC_iTPMS_Err 1;
BA_ "GenSigSendType" SG_ 1154 ESC_iTPMS_WarnLampAct 0;
BA_ "GenSigInvalidValue" SG_ 1154 ESC_iTPMS_WarnLampAct 1;
BA_ "GenSigSendType" SG_ 1154 ESC_iTPMSResetProhibit 0;
BA_ "GenSigSendType" SG_ 1154 ESC_iTPMSResetSts 0;
BA_ "GenSigSendType" SG_ 382 Checksum_0x17E 0;
BA_ "GenSigSendType" SG_ 382 Rolling_counter_0x17E 0;
BA_ "GenSigInvalidValue" SG_ 382 Rolling_counter_0x17E 15;
BA_ "GenSigSendType" SG_ 382 SAS_SteerWheelAngle 0;
BA_ "GenSigInvalidValue" SG_ 382 SAS_SteerWheelAngle 65535;
BA_ "GenSigStartValue" SG_ 382 SAS_SteerWheelAngle 32773;
BA_ "GenSigSendType" SG_ 382 SAS_SteeringAngleValid 0;
BA_ "GenSigSendType" SG_ 382 SAS_SASStsSnsr 0;
BA_ "GenSigSendType" SG_ 382 SAS_SteerWhlRotSpd 0;
BA_ "GenSigInvalidValue" SG_ 382 SAS_SteerWhlRotSpd 16383;
BA_ "GenSigSendType" SG_ 382 SAS_SteerWhlRotSpdStatus 0;
BA_ "GenSigSendType" SG_ 382 SAS_Calibrated 0;
BA_ "GenSigSendType" SG_ 382 SAS_SASFailure 0;
BA_ "GenSigSendType" SG_ 894 Checksum_0x37E 0;
BA_ "GenSigSendType" SG_ 894 Rolling_counter_0x37E 0;
BA_ "GenSigInvalidValue" SG_ 894 Rolling_counter_0x37E 15;
BA_ "GenSigSendType" SG_ 894 EPS_SteeringTorque 0;
BA_ "GenSigInvalidValue" SG_ 894 EPS_SteeringTorque 4095;
BA_ "GenSigSendType" SG_ 894 EPS_TorqSensorStatus 0;
BA_ "GenSigInvalidValue" SG_ 894 EPS_TorqSensorStatus 1;
BA_ "GenSigSendType" SG_ 894 EPS_EpsFailed 0;
BA_ "GenSigInvalidValue" SG_ 894 EPS_EpsFailed 1;
BA_ "GenSigStartValue" SG_ 894 EPS_EpsFailed 1;
BA_ "GenSigSendType" SG_ 894 EPS_Mode 0;
BA_ "GenSigInvalidValue" SG_ 894 EPS_Mode 3;
BA_ "GenSigSendType" SG_ 264 Checksum_0x108 0;
BA_ "GenSigSendType" SG_ 264 RollingCounter_0x108 0;
BA_ "GenSigInvalidValue" SG_ 264 RollingCounter_0x108 15;
BA_ "GenSigSendType" SG_ 264 EKS_DriveModeReq_reserved 0;
BA_ "GenSigSendType" SG_ 264 EKS_TargetGearReq 0;
BA_ "GenSigInvalidValue" SG_ 264 EKS_TargetGearReq 4;
BA_ "GenSigSendType" SG_ 264 EKS_Fault 0;
BA_ "GenSigSendType" SG_ 617 Checksum_0x269 0;
BA_ "GenSigSendType" SG_ 617 RollingCounter_0x269 0;
BA_ "GenSigInvalidValue" SG_ 617 RollingCounter_0x269 15;
BA_ "GenSigSendType" SG_ 617 VCU_VehicleHVStatus 0;
BA_ "GenSigInvalidValue" SG_ 617 VCU_VehicleHVStatus 3;
BA_ "GenSigSendType" SG_ 617 VCU_ActualGear 0;
BA_ "GenSigInvalidValue" SG_ 617 VCU_ActualGear 7;
BA_ "GenSigStartValue" SG_ 617 VCU_ActualGear 2;
BA_ "GenSigSendType" SG_ 617 VCU_ActualGearValid 0;
BA_ "GenSigInvalidValue" SG_ 617 VCU_ActualGearValid 1;
BA_ "GenSigSendType" SG_ 617 VCU_AccPedalPosition 0;
BA_ "GenSigInvalidValue" SG_ 617 VCU_AccPedalPosition 255;
BA_ "GenSigSendType" SG_ 617 VCU_AccPedalPositionValid 0;
BA_ "GenSigInvalidValue" SG_ 617 VCU_AccPedalPositionValid 1;
BA_ "GenSigSendType" SG_ 617 VCU_TqReductionRqstResponse 0;
BA_ "GenSigStartValue" SG_ 617 VCU_TqReductionRqstResponse 1;
BA_ "GenSigSendType" SG_ 617 VCU_BrakePedalSts 0;
BA_ "GenSigInvalidValue" SG_ 617 VCU_BrakePedalSts 3;
BA_ "GenSigSendType" SG_ 524 Checksum_0x20C 0;
BA_ "GenSigSendType" SG_ 524 Rolling_Counter_0x20C 0;
BA_ "GenSigInvalidValue" SG_ 524 Rolling_Counter_0x20C 15;
BA_ "GenSigSendType" SG_ 524 IPC_ODO 0;
BA_ "GenSigInvalidValue" SG_ 524 IPC_ODO 1048575;
BA_ "GenSigSendType" SG_ 703 IPC_TripA 0;
BA_ "GenSigInvalidValue" SG_ 703 IPC_TripA 65535;
BA_ "GenSigSendType" SG_ 703 IPC_AverageSpeedTripA 0;
BA_ "GenSigInvalidValue" SG_ 703 IPC_AverageSpeedTripA 4095;
BA_ "GenSigSendType" SG_ 703 IPC_AverageConsumptionTripA 0;
BA_ "GenSigInvalidValue" SG_ 703 IPC_AverageConsumptionTripA 1023;
BA_ "GenSigSendType" SG_ 703 IPC_ParkBrakeSts 0;
BA_ "GenSigInvalidValue" SG_ 703 IPC_ParkBrakeSts 3;
BA_ "GenSigSendType" SG_ 703 IPC_VehSpd 0;
BA_ "GenSigInvalidValue" SG_ 703 IPC_VehSpd 32767;
BA_ "GenSigSendType" SG_ 735 IPC_TireLearningReq_reserved 4;
BA_ "GenSigSendType" SG_ 735 IPC_TireResetReq 4;
BA_ "GenSigSendType" SG_ 1087 IPC_Sec 0;
BA_ "GenSigInvalidValue" SG_ 1087 IPC_Sec 63;
BA_ "GenSigSendType" SG_ 1087 IPC_Min 0;
BA_ "GenSigInvalidValue" SG_ 1087 IPC_Min 63;
BA_ "GenSigSendType" SG_ 1087 IPC_Hour 0;
BA_ "GenSigInvalidValue" SG_ 1087 IPC_Hour 31;
BA_ "GenSigSendType" SG_ 1087 IPC_Day 0;
BA_ "GenSigInvalidValue" SG_ 1087 IPC_Day 31;
BA_ "GenSigStartValue" SG_ 1087 IPC_Day 1;
BA_ "GenSigSendType" SG_ 1087 IPC_Month 0;
BA_ "GenSigInvalidValue" SG_ 1087 IPC_Month 15;
BA_ "GenSigStartValue" SG_ 1087 IPC_Month 1;
BA_ "GenSigSendType" SG_ 1087 IPC_Year 0;
BA_ "GenSigInvalidValue" SG_ 1087 IPC_Year 255;
BA_ "GenSigSendType" SG_ 1087 IPC_SelfCheckStatus 0;
BA_ "GenSigSendType" SG_ 814 CCU_ExternalTemperature 0;
BA_ "GenSigInvalidValue" SG_ 814 CCU_ExternalTemperature 255;
BA_ "GenSigStartValue" SG_ 814 CCU_ExternalTemperature 255;
BA_ "GenSigSendType" SG_ 814 CCU_ExternalTemperatureFailSts 0;
BA_ "GenSigInvalidValue" SG_ 814 CCU_ExternalTemperatureFailSts 1;
BA_ "GenSigStartValue" SG_ 814 CCU_ExternalTemperatureFailSts 1;
BA_ "GenSigSendType" SG_ 967 MHU_VehsSpd_Warn 2;
BA_ "GenSigInvalidValue" SG_ 967 MHU_VehsSpd_Warn 32767;
BA_ "GenSigStartValue" SG_ 967 MHU_VehsSpd_Warn 12000;
BA_ "GenSigSendType" SG_ 967 MHU_SET_Volume 2;
BA_ "GenSigInvalidValue" SG_ 967 MHU_SET_Volume 255;
BA_ "GenSigSendType" SG_ 967 MHU_St_DimmingIPC 2;
BA_ "GenSigInvalidValue" SG_ 967 MHU_St_DimmingIPC 15;
BA_ "GenSigStartValue" SG_ 967 MHU_St_DimmingIPC 10;
BA_ "GenSigSendType" SG_ 1027 Checksum_0x403 0;
BA_ "GenSigSendType" SG_ 1027 Rolling_Counter_0x403 0;
BA_ "GenSigInvalidValue" SG_ 1027 Rolling_Counter_0x403 15;
BA_ "GenSigSendType" SG_ 1027 MHU_SET_TCS_OnOff 2;
BA_ "GenSigInvalidValue" SG_ 1027 MHU_SET_TCS_OnOff 3;
BA_ "GenSigStartValue" SG_ 1027 MHU_SET_TCS_OnOff 2;
BA_ "GenSigSendType" SG_ 1027 MHU_SET_DrivingModeSwitch 2;
BA_ "GenSigSendType" SG_ 1027 MHU_SET_RegenLevel 2;
BA_ "GenSigStartValue" SG_ 1027 MHU_SET_RegenLevel 3;
BA_ "GenSigSendType" SG_ 1027 MHU_VCU_CreepDisable_stt 2;
BA_ "GenSigInvalidValue" SG_ 1027 MHU_VCU_CreepDisable_stt 3;
BA_ "GenSigSendType" SG_ 1027 MHU_ChargeSetTargetSOC 2;
BA_ "GenSigInvalidValue" SG_ 1027 MHU_ChargeSetTargetSOC 127;
BA_ "GenSigStartValue" SG_ 1027 MHU_ChargeSetTargetSOC 100;
BA_ "GenSigSendType" SG_ 1027 MHU_HVACTurnON 2;
BA_ "GenSigInvalidValue" SG_ 1027 MHU_HVACTurnON 3;
BA_ "GenSigSendType" SG_ 1027 MHU_ChargeScheduleSet 2;
BA_ "GenSigStartValue" SG_ 1027 MHU_ChargeScheduleSet 2;
BA_ "GenSigSendType" SG_ 1027 MHU_ChargingRequest 2;
BA_ "GenSigStartValue" SG_ 1027 MHU_ChargingRequest 3;
BA_ "GenSigSendType" SG_ 1027 MHU_ValetMode_Activation 2;
BA_ "GenSigInvalidValue" SG_ 1027 MHU_ValetMode_Activation 254;
BA_ "GenSigInactiveValue" SG_ 1027 MHU_ValetMode_Activation 255;
BA_ "GenSigSendType" SG_ 1027 MHU_ValetMode_MaxSpeed 2;
BA_ "GenSigInvalidValue" SG_ 1027 MHU_ValetMode_MaxSpeed 2;
BA_ "GenSigInactiveValue" SG_ 1027 MHU_ValetMode_MaxSpeed 255;
BA_ "GenSigSendType" SG_ 848 BCM_STAT_DoorAjarDriver 0;
BA_ "GenSigSendType" SG_ 848 BCM_PosLmpSts 0;
BA_ "GenSigSendType" SG_ 266 Checksum_0x10a 0;
BA_ "GenSigSendType" SG_ 266 Rolling_Counter_0x10a 0;
BA_ "GenSigInvalidValue" SG_ 266 Rolling_Counter_0x10a 15;
BA_ "GenSigSendType" SG_ 266 BCM_LVTop_up 0;
BA_ "GenSigSendType" SG_ 266 Ubatt_Reserved 0;
BA_ "GenSigInvalidValue" SG_ 266 Ubatt_Reserved 16383;
BA_ "GenSigStartValue" SG_ 266 Ubatt_Reserved 9000;
BA_ "GenSigSendType" SG_ 274 Checksum_0x112 0;
BA_ "GenSigSendType" SG_ 274 Rolling_Counter_0x112 0;
BA_ "GenSigInvalidValue" SG_ 274 Rolling_Counter_0x112 15;
BA_ "GenSigSendType" SG_ 274 STAT_Terminal 0;
BA_ "GenSigSendType" SG_ 274 STAT_CL30s_L_Reserved 0;
BA_ "GenSigStartValue" SG_ 274 STAT_CL30s_L_Reserved 3;
BA_ "GenSigSendType" SG_ 133 Checksum_0x85 0;
BA_ "GenSigSendType" SG_ 133 RollingCounter_0x85 0;
BA_ "GenSigInvalidValue" SG_ 133 RollingCounter_0x85 15;
BA_ "GenSigSendType" SG_ 133 ACM_Crash_Sts 0;
BA_ "GenSigSendType" SG_ 133 ACM_Airbag_Deployment_Status 0;
BA_ "GenSigSendType" SG_ 133 ACM_Crash_Intensity 0;
BA_ "GenSigSendType" SG_ 133 ACM_Front_Crash 0;
BA_ "GenSigSendType" SG_ 133 ACM_DriverSide_Crash 0;
BA_ "GenSigSendType" SG_ 133 ACM_PassSide_Crash 0;
BA_ "GenSigSendType" SG_ 133 ACM_Rear_Crash 0;
BA_ "GenSigSendType" SG_ 133 ACM_Rollover_Crash 0;
BA_ "GenSigSendType" SG_ 897 Checksum_0x381 0;
BA_ "GenSigSendType" SG_ 897 Rolling_Counter_0x381 0;
BA_ "GenSigInvalidValue" SG_ 897 Rolling_Counter_0x381 15;
BA_ "GenSigSendType" SG_ 897 ACM_Seat_Occupancy_Passenger 0;
BA_ "GenSigStartValue" SG_ 897 ACM_Seat_Occupancy_Passenger 2;
BA_ "GenSigSendType" SG_ 897 ACM_Seat_Occupancy_2nd_Row_Dri_reserved 0;
BA_ "GenSigStartValue" SG_ 897 ACM_Seat_Occupancy_2nd_Row_Dri_reserved 2;
BA_ "GenSigSendType" SG_ 897 ACM_Seat_Occupancy_2nd_Row_Pas_reserved 0;
BA_ "GenSigStartValue" SG_ 897 ACM_Seat_Occupancy_2nd_Row_Pas_reserved 2;
BA_ "GenSigSendType" SG_ 897 ACM_Seat_Occupancy_2nd_Row_Mid_reserved 0;
BA_ "GenSigStartValue" SG_ 897 ACM_Seat_Occupancy_2nd_Row_Mid_reserved 2;
BA_ "GenSigSendType" SG_ 897 ACM_Seat_Belt_Status_Passenger 0;
BA_ "GenSigSendType" SG_ 897 ACM_Seat_Belt_Status_Driver 0;
BA_ "GenSigSendType" SG_ 897 ACM_Seat_Belt_Status_2nd_Row_Dri_reserved 0;
BA_ "GenSigSendType" SG_ 897 ACM_Seat_Belt_Status_2nd_Row_Mid_reserved 0;
BA_ "GenSigSendType" SG_ 897 ACM_Seat_Belt_Status_2nd_Row_Pas_reserved 0;
BA_ "GenSigSendType" SG_ 897 ACM_Seat_Belt_Status_3rd_Row_Dri_reserved 0;
BA_ "GenSigStartValue" SG_ 897 ACM_Seat_Belt_Status_3rd_Row_Dri_reserved 2;
BA_ "GenSigSendType" SG_ 897 ACM_Seat_Belt_Status_3rd_Row_Pas_reserved 0;
BA_ "GenSigStartValue" SG_ 897 ACM_Seat_Belt_Status_3rd_Row_Pas_reserved 2;
BA_ "GenSigSendType" SG_ 533 Checksum_0x215 0;
BA_ "GenSigSendType" SG_ 533 Rolling_Counter_0x215 0;
BA_ "GenSigInvalidValue" SG_ 533 Rolling_Counter_0x215 15;
BA_ "GenSigSendType" SG_ 533 BMS_SOE 0;
BA_ "GenSigInvalidValue" SG_ 533 BMS_SOE 255;
BA_ "GenSigStartValue" SG_ 533 BMS_SOE 54;
BA_ "GenSigSendType" SG_ 533 BMS_HWCrash_Sts 0;
BA_ "GenSigSendType" SG_ 533 BMS_HVIL_STS 0;
BA_ "GenSigSendType" SG_ 533 BMS_IGN_Sts 0;
BA_ "GenSigSendType" SG_ 533 BMS_Sys_STS 0;
BA_ "GenSigInvalidValue" SG_ 533 BMS_Sys_STS 8;
BA_ "GenSigSendType" SG_ 533 BMS_HVOnOff_STS 0;
BA_ "GenSigSendType" SG_ 533 BMS_Balance_STS 0;
BA_ "GenSigSendType" SG_ 533 BMS_SocActual_EST 0;
BA_ "GenSigInvalidValue" SG_ 533 BMS_SocActual_EST 1023;
BA_ "GenSigSendType" SG_ 533 BMS_BatBalance_ERR 0;
BA_ "GenSigSendType" SG_ 533 BMS_ISU_Status 0;
BA_ "GenSigSendType" SG_ 533 BMS_ERR_LEV 0;
BA_ "GenSigInvalidValue" SG_ 533 BMS_ERR_LEV 15;
BA_ "GenSigSendType" SG_ 533 BMS_SOH 0;
BA_ "GenSigInvalidValue" SG_ 533 BMS_SOH 255;
BA_ "GenSigStartValue" SG_ 533 BMS_SOH 54;
BA_ "GenSigSendType" SG_ 533 BMS_HV_Sts 0;
BA_ "GenSigSendType" SG_ 504 Checksum_0x1F8 0;
BA_ "GenSigSendType" SG_ 504 Rolling_Counter_0x1F8 0;
BA_ "GenSigInvalidValue" SG_ 504 Rolling_Counter_0x1F8 15;
BA_ "GenSigSendType" SG_ 504 EDS_output_trq_FR 0;
BA_ "GenSigInvalidValue" SG_ 504 EDS_output_trq_FR 65535;
BA_ "GenSigStartValue" SG_ 504 EDS_output_trq_FR 2000;
BA_ "GenSigSendType" SG_ 504 EDS_output_trqValid_FR 0;
BA_ "GenSigSendType" SG_ 504 EDS_Spd_FR 0;
BA_ "GenSigInvalidValue" SG_ 504 EDS_Spd_FR 65535;
BA_ "GenSigStartValue" SG_ 504 EDS_Spd_FR 20000;
BA_ "GenSigSendType" SG_ 504 EDS_SpdValid_FR 0;
BA_ "GenSigSendType" SG_ 504 EDS_MotorDriveSts_FR 0;
BA_ "GenSigInvalidValue" SG_ 504 EDS_MotorDriveSts_FR 3;
BA_ "GenSigSendType" SG_ 504 EDS_Work_STS_FR 0;
BA_ "GenSigInvalidValue" SG_ 504 EDS_Work_STS_FR 15;
BA_ "GenSigSendType" SG_ 504 EDS_powoff_req_FR 0;
BA_ "GenSigSendType" SG_ 889 VCU_DriveCoolWaterPumpSts 0;
BA_ "GenSigSendType" SG_ 889 VCU_DriveCoolWaterDuty 0;
BA_ "GenSigInvalidValue" SG_ 889 VCU_DriveCoolWaterDuty 127;
BA_ "GenSigSendType" SG_ 889 VCU_BatteryWaterPumpSts_reserved 0;
BA_ "GenSigSendType" SG_ 889 VCU_BatteryWaterPumpDuty_reserved 0;
BA_ "GenSigInvalidValue" SG_ 889 VCU_BatteryWaterPumpDuty_reserved 127;
BA_ "GenSigSendType" SG_ 889 VCU_DriveMode 0;
BA_ "GenSigInvalidValue" SG_ 889 VCU_DriveMode 7;
BA_ "GenSigStartValue" SG_ 889 VCU_DriveMode 1;
BA_ "GenSigSendType" SG_ 889 VCU_ActualGear 0;
BA_ "GenSigInvalidValue" SG_ 889 VCU_ActualGear 7;
BA_ "GenSigStartValue" SG_ 889 VCU_ActualGear 2;
BA_ "GenSigSendType" SG_ 889 VCU_ACTGearValid 0;
BA_ "GenSigInvalidValue" SG_ 889 VCU_ACTGearValid 1;
BA_ "GenSigSendType" SG_ 889 VCU_AccPedal1OutRange 0;
BA_ "GenSigSendType" SG_ 889 VCU_AccPedal2OutRange 0;
BA_ "GenSigSendType" SG_ 889 VCU_BrkPedal1OutRange 0;
BA_ "GenSigSendType" SG_ 889 VCU_BrkPedal2OutRange 0;
BA_ "GenSigSendType" SG_ 889 VCU_BrkPedalPct 0;
BA_ "GenSigInvalidValue" SG_ 889 VCU_BrkPedalPct 255;
BA_ "GenSigSendType" SG_ 889 VCU_AccPedalPosition 0;
BA_ "GenSigInvalidValue" SG_ 889 VCU_AccPedalPosition 255;
BA_ "GenSigSendType" SG_ 889 VCU_AccPedalPositionValid 0;
BA_ "GenSigInvalidValue" SG_ 889 VCU_AccPedalPositionValid 1;
BA_ "GenSigStartValue" SG_ 889 VCU_AccPedalPositionValid 1;
BA_ "GenSigSendType" SG_ 889 VCU_SocDisplay_EST 0;
BA_ "GenSigInvalidValue" SG_ 889 VCU_SocDisplay_EST 127;
BA_ "GenSigSendType" SG_ 889 VCU_PowerLimit 0;
BA_ "GenSigSendType" SG_ 889 VCU_CruiseCtrlSts 0;
BA_ "GenSigSendType" SG_ 889 VCU_LowSOC_ERR 0;
BA_ "GenSigSendType" SG_ 1705 ESC_DiagReqData0 0;
BA_ "GenSigSendType" SG_ 1705 ESC_DiagReqData1 0;
BA_ "GenSigSendType" SG_ 1705 ESC_DiagReqData2 0;
BA_ "GenSigSendType" SG_ 1705 ESC_DiagReqData3 0;
BA_ "GenSigSendType" SG_ 1705 ESC_DiagReqData4 0;
BA_ "GenSigSendType" SG_ 1705 ESC_DiagReqData5 0;
BA_ "GenSigSendType" SG_ 1705 ESC_DiagReqData6 0;
BA_ "GenSigSendType" SG_ 1705 ESC_DiagReqData7 0;
BA_ "GenSigSendType" SG_ 1577 ESC_DiagRespData0 0;
BA_ "GenSigSendType" SG_ 1577 ESC_DiagRespData1 0;
BA_ "GenSigSendType" SG_ 1577 ESC_DiagRespData2 0;
BA_ "GenSigSendType" SG_ 1577 ESC_DiagRespData3 0;
BA_ "GenSigSendType" SG_ 1577 ESC_DiagRespData4 0;
BA_ "GenSigSendType" SG_ 1577 ESC_DiagRespData5 0;
BA_ "GenSigSendType" SG_ 1577 ESC_DiagRespData6 0;
BA_ "GenSigSendType" SG_ 1577 ESC_DiagRespData7 0;
BA_ "GenSigSendType" SG_ 1704 EPS_DiagReqData0 0;
BA_ "GenSigSendType" SG_ 1704 EPS_DiagReqData1 0;
BA_ "GenSigSendType" SG_ 1704 EPS_DiagReqData2 0;
BA_ "GenSigSendType" SG_ 1704 EPS_DiagReqData3 0;
BA_ "GenSigSendType" SG_ 1704 EPS_DiagReqData4 0;
BA_ "GenSigSendType" SG_ 1704 EPS_DiagReqData5 0;
BA_ "GenSigSendType" SG_ 1704 EPS_DiagReqData6 0;
BA_ "GenSigSendType" SG_ 1704 EPS_DiagReqData7 0;
BA_ "GenSigSendType" SG_ 1576 EPS_DiagRespData0 0;
BA_ "GenSigSendType" SG_ 1576 EPS_DiagRespData1 0;
BA_ "GenSigSendType" SG_ 1576 EPS_DiagRespData2 0;
BA_ "GenSigSendType" SG_ 1576 EPS_DiagRespData3 0;
BA_ "GenSigSendType" SG_ 1576 EPS_DiagRespData4 0;
BA_ "GenSigSendType" SG_ 1576 EPS_DiagRespData5 0;
BA_ "GenSigSendType" SG_ 1576 EPS_DiagRespData6 0;
BA_ "GenSigSendType" SG_ 1576 EPS_DiagRespData7 0;
BA_ "GenSigSendType" SG_ 1680 EKS_DiagReqData0 0;
BA_ "GenSigSendType" SG_ 1680 EKS_DiagReqData1 0;
BA_ "GenSigSendType" SG_ 1680 EKS_DiagReqData2 0;
BA_ "GenSigSendType" SG_ 1680 EKS_DiagReqData3 0;
BA_ "GenSigSendType" SG_ 1680 EKS_DiagReqData4 0;
BA_ "GenSigSendType" SG_ 1680 EKS_DiagReqData5 0;
BA_ "GenSigSendType" SG_ 1680 EKS_DiagReqData6 0;
BA_ "GenSigSendType" SG_ 1680 EKS_DiagReqData7 0;
BA_ "GenSigSendType" SG_ 1552 EKS_DiagRespData0 0;
BA_ "GenSigSendType" SG_ 1552 EKS_DiagRespData1 0;
BA_ "GenSigSendType" SG_ 1552 EKS_DiagRespData2 0;
BA_ "GenSigSendType" SG_ 1552 EKS_DiagRespData3 0;
BA_ "GenSigSendType" SG_ 1552 EKS_DiagRespData4 0;
BA_ "GenSigSendType" SG_ 1552 EKS_DiagRespData5 0;
BA_ "GenSigSendType" SG_ 1552 EKS_DiagRespData6 0;
BA_ "GenSigSendType" SG_ 1552 EKS_DiagRespData7 0;
BA_ "GenSigSendType" SG_ 1706 AVAS_DiagReqData0 0;
BA_ "GenSigSendType" SG_ 1706 AVAS_DiagReqData1 0;
BA_ "GenSigSendType" SG_ 1706 AVAS_DiagReqData2 0;
BA_ "GenSigSendType" SG_ 1706 AVAS_DiagReqData3 0;
BA_ "GenSigSendType" SG_ 1706 AVAS_DiagReqData4 0;
BA_ "GenSigSendType" SG_ 1706 AVAS_DiagReqData5 0;
BA_ "GenSigSendType" SG_ 1706 AVAS_DiagReqData6 0;
BA_ "GenSigSendType" SG_ 1706 AVAS_DiagReqData7 0;
BA_ "GenSigSendType" SG_ 1578 AVAS_DiagRespData0 0;
BA_ "GenSigSendType" SG_ 1578 AVAS_DiagRespData1 0;
BA_ "GenSigSendType" SG_ 1578 AVAS_DiagRespData2 0;
BA_ "GenSigSendType" SG_ 1578 AVAS_DiagRespData3 0;
BA_ "GenSigSendType" SG_ 1578 AVAS_DiagRespData4 0;
BA_ "GenSigSendType" SG_ 1578 AVAS_DiagRespData5 0;
BA_ "GenSigSendType" SG_ 1578 AVAS_DiagRespData6 0;
BA_ "GenSigSendType" SG_ 1578 AVAS_DiagRespData7 0;
BA_ "GenSigSendType" SG_ 1791 GW_DiagFunctionalAddressingData0 0;
BA_ "GenSigSendType" SG_ 1791 GW_DiagFunctionalAddressingData1 0;
BA_ "GenSigSendType" SG_ 1791 GW_DiagFunctionalAddressingData2 0;
BA_ "GenSigSendType" SG_ 1791 GW_DiagFunctionalAddressingData3 0;
BA_ "GenSigSendType" SG_ 1791 GW_DiagFunctionalAddressingData4 0;
BA_ "GenSigSendType" SG_ 1791 GW_DiagFunctionalAddressingData5 0;
BA_ "GenSigSendType" SG_ 1791 GW_DiagFunctionalAddressingData6 0;
BA_ "GenSigSendType" SG_ 1791 GW_DiagFunctionalAddressingData7 0;
VAL_ 306 RollingCounter_0x132 15 "Invalid";
VAL_ 306 ESC_HSA_Control_Status 1 "active" 0 "inactive";
VAL_ 306 ESC_HSA_Status_Fault 1 " HSA Defective" 0 "HSA Normale";
VAL_ 306 ESC_TcsDisableSts 3 "signal invalid" 2 "reservred" 1 "disabled" 0 "enabled";
VAL_ 306 ESC_TcsCtrlActv 1 "active" 0 "inactive";
VAL_ 306 ESC_TcsFlgFlt 1 "failure" 0 "no failure";
VAL_ 306 ESC_EscDisableSts 1 "disabled" 0 "enabled";
VAL_ 306 ESC_EscCtrlActv 1 "active" 0 "inactive";
VAL_ 306 ESC_EscFlgFlt 1 "failure" 0 "no failure";
VAL_ 306 ESC_HBAFlgFlt 1 "failure" 0 "no failure";
VAL_ 306 ESC_HbaCtrlActv 1 "active" 0 "inactive";
VAL_ 306 ESC_SlopeGradeAngle 255 "Invalid";
VAL_ 306 ESC_MasterCylinderPressure 4095 "Invalid";
VAL_ 322 RollingCounter_0x142 15 "Invalid";
VAL_ 322 AbsDiagSessionLampReq_Reserved 1 "lamp on" 0 "lamp off";
VAL_ 322 ABS_AbsCtrlActv 1 "active" 0 "inactive";
VAL_ 322 ABS_EbdFlgFlt 1 "failure" 0 "no failure";
VAL_ 322 ABS_AbsFlgFlt 1 "failure" 0 "no failure";
VAL_ 322 ABS_ESS_Active 1 "active" 0 "inactive";
VAL_ 322 ABS_LowBrakeFluid 1 "failure" 0 "no failure";
VAL_ 818 RollingCounter_0x332 15 "Invalid";
VAL_ 818 ABS_LFWhlSpdRaw 32767 "Invalid";
VAL_ 818 ABS_LFWhlSpdRawValid 1 "Valid" 0 "Invalid";
VAL_ 818 ABS_RFWhlSpdRaw 32767 "Invalid";
VAL_ 818 ABS_RFWhlSpdRawValid 1 "Valid" 0 "Invalid";
VAL_ 834 RollingCounter_0x342 15 "Invalid";
VAL_ 834 ABS_LRWhlSpdRaw 32767 "Invalid";
VAL_ 834 ABS_LRWhlSpdRawValid 1 "Valid" 0 "Invalid";
VAL_ 834 ABS_RRWhlSpdRaw 32767 "Invalid";
VAL_ 834 ABS_RRWhlSpdRawValid 1 "Valid" 0 "Invalid";
VAL_ 834 ABS_VehSpd 32767 "Invalid";
VAL_ 834 ABS_VehSpdValid 1 "Valid" 0 "Invalid";
VAL_ 610 ABS_WssLFPulseCounter 32767 "Invalid";
VAL_ 610 ABS_WssLFPulseCounterValid 1 "Valid" 0 "Invalid";
VAL_ 610 ABS_WssRFPulseCounter 32767 "Invalid";
VAL_ 610 ABS_WssRFPulseCounterValid 1 "Valid" 0 "Invalid";
VAL_ 610 ABS_WssLRPulseCounter 32767 "Invalid";
VAL_ 610 ABS_WssLRPulseCounterValid 1 "Valid" 0 "Invalid";
VAL_ 610 ABS_WssRRPulseCounter 32767 "Invalid";
VAL_ 610 ABS_WssRRPulseCounterValid 1 "Valid" 0 "Invalid";
VAL_ 994 RollingCounter_0x3E2 15 "Invalid";
VAL_ 994 ESC_LateralACC 255 "Invalid";
VAL_ 994 ESC_LateralACC_Valid 1 "Valid" 0 "Invalid";
VAL_ 994 ESC_LongitudeACC 1023 "Invalid";
VAL_ 994 ESC_LongitudeACC_Valid 1 "Valid" 0 "Invalid";
VAL_ 994 ESC_VehDynYawRate 16383 "Invalid";
VAL_ 994 ESC_VehDynYawRate_Valid 1 "Valid" 0 "Invalid";
VAL_ 1010 RollingCounter_0x3F2 15 "Invalid";
VAL_ 1010 ESC_VehicleACC 1023 "Invalid";
VAL_ 1010 ESC_VehicleACC_Valid 1 "Valid" 0 "Invalid";
VAL_ 866 RollingCounter_362 15 "Invalid";
VAL_ 866 ESC_RegenDragCtrlStatus 1 "active" 0 "inactive";
VAL_ 866 ESC_RegenBrakeCtrlStatus 1 "active" 0 "inactive";
VAL_ 866 ESC_TorqReqMode 3 "Reserved" 2 "Regen mode" 1 "TCS mode" 0 "Normal mode";
VAL_ 866 ESC_TorqRequestVal 65535 "Invalid";
VAL_ 1154 ESC_FLTirePressAlarm 1 "Pressure warning" 0 "No warning";
VAL_ 1154 ESC_FRTirePressAlarm 1 "Pressure warning" 0 "No warning";
VAL_ 1154 ESC_RLTirePressAlarm 1 "Pressure warning" 0 "No warning";
VAL_ 1154 ESC_RRTirePressAlarm 1 "Pressure warning" 0 "No warning";
VAL_ 1154 ESC_iTPMS_Err 1 "Error" 0 "No error";
VAL_ 1154 ESC_iTPMS_WarnLampAct 1 "Active" 0 "Inactive";
VAL_ 1154 ESC_iTPMSResetProhibit 3 "prohibit 3 (System error)" 2 "prohibit 2 (Vehicle speed >0 km/h)" 1 "prohibit 1 (Tire statue is changing)" 0 "Not prohibit";
VAL_ 1154 ESC_iTPMSResetSts 4 "Reset fail" 3 "Reset finish" 2 "Reset ongoing" 1 "Reset start" 0 "Idle";
VAL_ 382 Rolling_counter_0x17E 15 "Invalid";
VAL_ 382 SAS_SteerWheelAngle 65535 "Invalid";
VAL_ 382 SAS_SteeringAngleValid 1 "Valid" 0 "Invalid";
VAL_ 382 SAS_SASStsSnsr 1 "sensor value valid" 0 "sensor value Invalid";
VAL_ 382 SAS_SteerWhlRotSpd 16383 "Invalid";
VAL_ 382 SAS_SteerWhlRotSpdStatus 1 "Valid" 0 "Invalid";
VAL_ 382 SAS_Calibrated 1 "Calibrated" 0 "Not Calibrated";
VAL_ 382 SAS_SASFailure 1 "No Failure" 0 "Failure";
VAL_ 894 Rolling_counter_0x37E 15 "Invalid";
VAL_ 894 EPS_SteeringTorque 4095 "Invalid";
VAL_ 894 EPS_TorqSensorStatus 1 "Invalid" 0 "Valid";
VAL_ 894 EPS_EpsFailed 1 "failed" 0 "not failed";
VAL_ 894 EPS_Mode 3 " Invalid" 1 "low assist" 0 "full assist";
VAL_ 264 RollingCounter_0x108 15 "Invalid";
VAL_ 264 EKS_DriveModeReq_reserved 1 "press" 0 "no press";
VAL_ 264 EKS_TargetGearReq 7 "Reserved" 4 "Invalid" 3 "D" 2 "N" 1 "R" 0 "P reserved";
VAL_ 264 EKS_Fault 5 "Received Date from VCU is invalid" 4 "Supply voltage failure" 3 "Position sensor failure" 2 "CAN communication fail" 1 "Shifter failure" 0 "normal";
VAL_ 617 RollingCounter_0x269 15 "Invalid";
VAL_ 617 VCU_VehicleHVStatus 3 "Reserved" 2 "ReadyToDrive" 1 "HV On" 0 "Not ready";
VAL_ 617 VCU_ActualGear 7 "Fault" 6 "Reserved" 5 "Reserved" 4 "Reserved" 3 "D" 2 "N" 1 "R" 0 "P reserved";
VAL_ 617 VCU_ActualGearValid 1 "Invalid" 0 "Valid";
VAL_ 617 VCU_AccPedalPosition 255 "Invalid";
VAL_ 617 VCU_AccPedalPositionValid 1 "Invalid" 0 "Valid";
VAL_ 617 VCU_TqReductionRqstResponse 1 "active" 0 "inactive";
VAL_ 617 VCU_BrakePedalSts 3 "Invalid" 2 "Reserved" 1 "pressed" 0 "Not pressed";
VAL_ 524 Rolling_Counter_0x20C 15 "Invalid";
VAL_ 524 IPC_ODO 1048575 "Invalid";
VAL_ 703 IPC_TripA 65535 "Invalid";
VAL_ 703 IPC_AverageSpeedTripA 4095 "Invalid";
VAL_ 703 IPC_AverageConsumptionTripA 1023 "Invalid";
VAL_ 703 IPC_ParkBrakeSts 3 "Invalid" 2 "Reserved" 1 "Applied" 0 "Released";
VAL_ 703 IPC_VehSpd 32767 "Invalid";
VAL_ 735 IPC_TireLearningReq_reserved 3 "Reserved" 2 "Reserved" 1 "Requset" 0 "No requset";
VAL_ 735 IPC_TireResetReq 3 "Reserved" 2 "Reserved" 1 "Requset to reset" 0 "No requset";
VAL_ 1087 IPC_Sec 63 "Invalid";
VAL_ 1087 IPC_Min 63 "Invalid";
VAL_ 1087 IPC_Hour 31 "Invalid";
VAL_ 1087 IPC_Day 31 "Invalid";
VAL_ 1087 IPC_Month 15 "Invalid";
VAL_ 1087 IPC_Year 255 "Invalid";
VAL_ 1087 IPC_SelfCheckStatus 1 "self-check finish" 0 "self-checking";
VAL_ 814 CCU_ExternalTemperature 255 "Invaild";
VAL_ 814 CCU_ExternalTemperatureFailSts 1 "invalid" 0 "valid";
VAL_ 967 MHU_St_DimmingIPC 15"Invalid" 14"Level 15" 13 "Level 14" 12 "Level 13" 11 "Level 12" 10 "Level 11" 9"Level 10" 8 "Level 9" 7 "Level 8" 6 "Level 7" 5 "Level 6" 4 "Level 5" 3 "Level 4" 2 "Level 3" 1"Level 2" 0"Level 1";
VAL_ 1027 Rolling_Counter_0x403 15 "Invalid";
VAL_ 1027 MHU_SET_TCS_OnOff 0 "OFF (keep sending for 2 seconds)" 1 "ON (keep sending for 2 seconds)" 2 "No action" 3 "Invalid";
VAL_ 1027 MHU_SET_DrivingModeSwitch 3 "sport mode (should be hold during 1 second)" 2 "normal mode (should be hold during 1 second)" 1 "eco mode (should be hold during 1 second)" 0 "no change request";
VAL_ 1027 MHU_SET_RegenLevel 3 "No action" 2 "High" 1 "Low" 0 "none";
VAL_ 1027 MHU_VCU_CreepDisable_stt 0 "No request" 1 "Creep Disable request" 2 "Reserved" 3 "Invalid";
VAL_ 1027 MHU_HVACTurnON 0 "No request" 1 "ON" 2 "Reserved" 3 "Invalid";
VAL_ 1027 MHU_ChargeScheduleSet 0 "Disabled" 1 "Enabled" 2 "No Action" 3 "Reserved";
VAL_ 1027 MHU_ChargingRequest 0 "Reserved" 1 "Request scheduled start charging" 2 "Request stop" 3 "No effect";
VAL_ 1027 MHU_ValetMode_Activation 0 "Inactive" 1 "Active" 254 "Reserved" 255 "Invalid";
VAL_ 848 BCM_STAT_DoorAjarDriver 3 "Signal invalid" 2 "Reserved" 1 "Opened" 0 "Closed";
VAL_ 848 BCM_PosLmpSts 0 "OFF" 1 "ON" 2 "Fault (Reserved)" 3 "Signal Invalid";
VAL_ 266 Rolling_Counter_0x10a 15 "Invalid";
VAL_ 266 BCM_LVTop_up 1 "start Top up" 0 "stop Top up";
VAL_ 274 Rolling_Counter_0x112 15 "Invalid";
VAL_ 274 STAT_Terminal 7 "Signal invalid" 6 "Reserved" 5 "Reserved" 4 "SW update OTA (Not used in VFe34)" 3 "Engine start (eMotor running)" 2 "ON (Driver Present)" 1 "ACC (Park)" 0 "OFF(Comfort Enable)";
VAL_ 274 STAT_CL30s_L_Reserved 3 "Signal invalid" 2 "Failure" 1 "ON" 0 "OFF";
VAL_ 133 RollingCounter_0x85 15 "Invalid";
VAL_ 133 ACM_Crash_Sts 3 "Invalid Value" 2 "Invalid Value" 1 "Crash_Detected" 0 "No_Event";
VAL_ 133 ACM_Airbag_Deployment_Status 3 "Invalid Value" 2 "Invalid Value" 1 "Airbag_Deployment" 0 "No_Airbag_Deployment";
VAL_ 133 ACM_Crash_Intensity 7 "Invalid_Value" 6 "Invalid_Value" 5 "Invalid_Value" 4 "Invalid_Value" 3 "Crash_Intensity_3" 2 "Crash_Intensity_2" 1 "Crash_Intensity_1" 0 "No_Crash";
VAL_ 133 ACM_Front_Crash 3 "Invalid Value" 2 "Invalid Value" 1 "Front_Crash_Detected" 0 "No_Event";
VAL_ 133 ACM_DriverSide_Crash 3 "Invalid Value" 2 "Invalid Value" 1 "Driverside_Crash_Detected" 0 "No_Event";
VAL_ 133 ACM_PassSide_Crash 3 "Invalid Value" 2 "Invalid Value" 1 "PassSide_Crash_Detected" 0 "No_Event";
VAL_ 133 ACM_Rear_Crash 3 "Invalid Value" 2 "Invalid Value" 1 "Rear_Crash_Detected" 0 "No_Event";
VAL_ 133 ACM_Rollover_Crash 3 "Invalid Value" 2 "Invalid Value" 1 "Rollover_Crash_Detected" 0 "No_Event";
VAL_ 897 Rolling_Counter_0x381 15 "Invalid";
VAL_ 897 ACM_Seat_Occupancy_Passenger 3 "Failure" 2 "Not_Available" 1 "Seat Occupied" 0 "Seat_Not_Occupied";
VAL_ 897 ACM_Seat_Occupancy_2nd_Row_Dri_reserved 3 "Failure" 2 "Not_Available" 1 "Seat Occupied" 0 "Seat_Not_Occupied";
VAL_ 897 ACM_Seat_Occupancy_2nd_Row_Pas_reserved 3 "Failure" 2 "Not_Available" 1 "Seat Occupied" 0 "Seat_Not_Occupied";
VAL_ 897 ACM_Seat_Occupancy_2nd_Row_Mid_reserved 3 "Failure" 2 "Not_Available" 1 "Seat Occupied" 0 "Seat_Not_Occupied";
VAL_ 897 ACM_Seat_Belt_Status_Passenger 3 "Failure" 2 "Not_Available" 1 "Buckled" 0 "Not_buckled";
VAL_ 897 ACM_Seat_Belt_Status_Driver 3 "Failure" 2 "Not_Available" 1 "Buckled" 0 "Not_buckled";
VAL_ 897 ACM_Seat_Belt_Status_2nd_Row_Dri_reserved 3 "Failure" 2 "Not_Available" 1 "Buckled" 0 "Not_buckled";
VAL_ 897 ACM_Seat_Belt_Status_2nd_Row_Mid_reserved 3 "Failure" 2 "Not_Available" 1 "Buckled" 0 "Not_buckled";
VAL_ 897 ACM_Seat_Belt_Status_2nd_Row_Pas_reserved 3 "Failure" 2 "Not_Available" 1 "Buckled" 0 "Not_buckled";
VAL_ 897 ACM_Seat_Belt_Status_3rd_Row_Dri_reserved 3 "Failure" 2 "Not_Available" 1 "Buckled" 0 "Not_buckled";
VAL_ 897 ACM_Seat_Belt_Status_3rd_Row_Pas_reserved 3 "Failure" 2 "Not_Available" 1 "Buckled" 0 "Not_buckled";
VAL_ 533 Rolling_Counter_0x215 15 "Invalid";
VAL_ 533 BMS_SOE 255 "Invalid";
VAL_ 533 BMS_HWCrash_Sts 1 "Crash " 0 "No Crash";
VAL_ 533 BMS_HVIL_STS 2 "short to ground" 1 "Open & short to battery" 0 "Closed";
VAL_ 533 BMS_IGN_Sts 1 "ON " 0 "OFF";
VAL_ 533 BMS_Sys_STS 8 "Invalid" 7 "Failure, unable to operate" 6 "BCU Sleep mode" 5 "Successful Power Down" 4 "Power Down process" 3 "Successful Power Down of HV" 2 "Successful High Voltage Power Up" 1 "Self-check passes, can be high-voltage" 0 "Initialization of power on, self-checking";
VAL_ 533 BMS_HVOnOff_STS 3 "Fail to HV on " 2 "HV On " 1 "Precharge " 0 "HV Off";
VAL_ 533 BMS_Balance_STS 1 "active " 0 "Inactive";
VAL_ 533 BMS_SocActual_EST 1023 "Invalid";
VAL_ 533 BMS_BatBalance_ERR 1 "normal " 0 "Error";
VAL_ 533 BMS_ISU_Status 3 "Level3(<100 Ohms/V)" 2 "Level2(<200 Ohms/V)" 1 "Level1 <500 Ohms/V ~ >200 Ohms/V" 0 "Normal (> 500 Ohms/V)";
VAL_ 533 BMS_ERR_LEV 7 "Battery locked -Reserved" 6 "Fault, needs Shutdown and Wakeup" 5 "Emergency off condition" 4 "Delayed power down with FTTI" 3 "Power down without FTTI" 2 "Limp Home" 1 " Warning (any warning in system)" 0 "No error";
VAL_ 533 BMS_SOH 255 "Invalid";
VAL_ 533 BMS_HV_Sts 4 "AC Charge" 3 "Super Fast Charge" 2 "HV ON" 1 "Precharge" 0 "HV Off";
VAL_ 504 Rolling_Counter_0x1F8 15 "Invalid";
VAL_ 504 EDS_output_trq_FR 65535 "Invalid";
VAL_ 504 EDS_output_trqValid_FR 1 "valid" 0 "invalid";
VAL_ 504 EDS_Spd_FR 65535 "Invalid";
VAL_ 504 EDS_SpdValid_FR 1 "valid" 0 "invalid";
VAL_ 504 EDS_MotorDriveSts_FR 3 "Invaild" 2 "regen control" 1 "Drive control" 0 "Zero control";
VAL_ 504 EDS_Work_STS_FR 15 "invaild" 14 "power off" 13 "Failure" 12 "after run" 11 "shut down" 5 "HVReady" 4 "normal" 3 "precharge" 2 "standby" 1 "init" 0 "default";
VAL_ 504 EDS_powoff_req_FR 1 "(Request high voltage power down)" 0 "(No request)";
VAL_ 889 VCU_DriveCoolWaterPumpSts 5 "Reserved" 4 "Other error" 3 "Overtemperature" 2 "Locked-rotor" 1 "Idle" 0 "Normal";
VAL_ 889 VCU_DriveCoolWaterDuty 127 "Invalid";
VAL_ 889 VCU_BatteryWaterPumpSts_reserved 5 "Reserved" 4 "Other error" 3 "Overtemperature" 2 "Locked-rotor" 1 "Idle" 0 "Normal";
VAL_ 889 VCU_BatteryWaterPumpDuty_reserved 127 "Invalid";
VAL_ 889 VCU_DriveMode 7 "Invalid" 6 "Reserved" 5 "Reserved" 4 "Reserved" 3 "Reserved" 2 "Sport mode" 1 "ECO mode" 0 "Normal mode";
VAL_ 889 VCU_ActualGear 7 "Fault" 6 "Reserved" 5 "Reserved" 4 "Reserved" 3 "D" 2 "N" 1 "R" 0 "P reserved";
VAL_ 889 VCU_ACTGearValid 1 "nvalid" 0 "Valid";
VAL_ 889 VCU_AccPedal1OutRange 1 "Error" 0 "Normal";
VAL_ 889 VCU_AccPedal2OutRange 1 "Error" 0 "Normal";
VAL_ 889 VCU_BrkPedal1OutRange 1 "Error" 0 "Normal";
VAL_ 889 VCU_BrkPedal2OutRange 1 "Error" 0 "Normal";
VAL_ 889 VCU_BrkPedalPct 255 "Invalid";
VAL_ 889 VCU_AccPedalPosition 255 "Invalid";
VAL_ 889 VCU_AccPedalPositionValid 1 "Invalid" 0 "Valid";
VAL_ 889 VCU_SocDisplay_EST 127 "Invalid";
VAL_ 889 VCU_PowerLimit 1 "Limit" 0 "No Limit";
VAL_ 889 VCU_CruiseCtrlSts 3 "takeover mode" 2 "Pre cruise(lamp flash)" 1 "Cruise on(lamp on)" 0 "Cruise off(lamp off)";
VAL_ 889 VCU_LowSOC_ERR 1 "Error" 0 "No Error";
